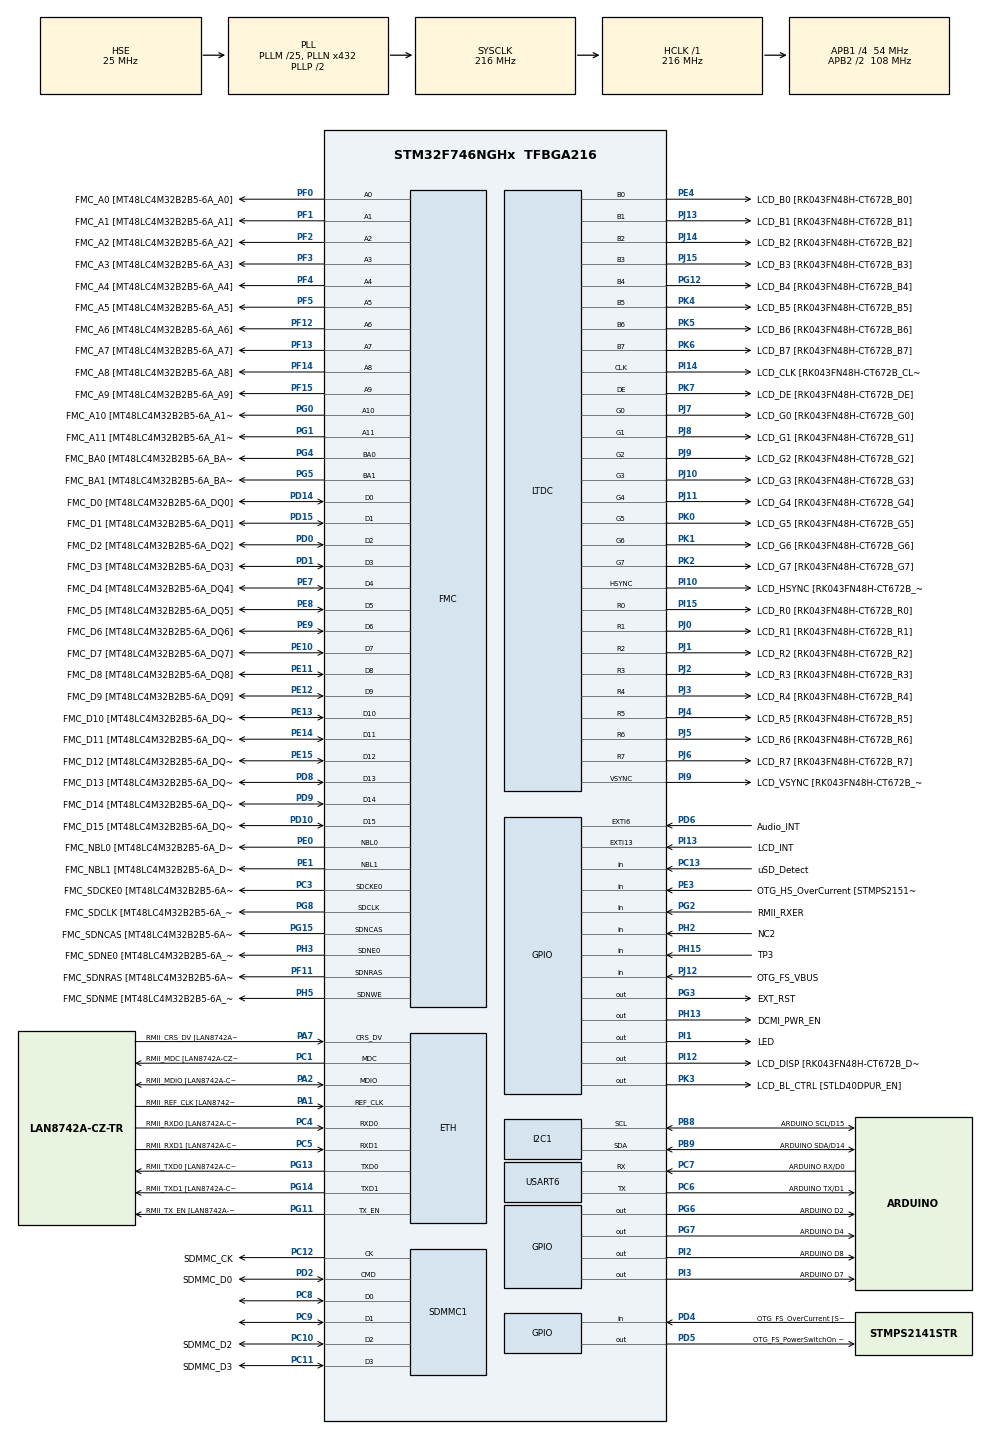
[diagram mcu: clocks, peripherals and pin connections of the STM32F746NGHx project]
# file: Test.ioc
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ETH.MediaInterface=HAL_ETH_RMII_MODE
FATFS.BSP.number=1
FATFS._USE_LFN=1
FATFS0.BSP.STBoard=false
FATFS0.BSP.api=Unknown
FATFS0.BSP.instance=PC13
FATFS0.BSP.ip=GPIO
FATFS0.BSP.mode=Input
FATFS0.BSP.name=Detect_SDIO
FATFS0.BSP.solution=PC13
FMC.CASLatency1=FMC_SDRAM_CAS_LATENCY_3
FMC.ExitSelfRefreshDelay1=7
FMC.LoadToActiveDelay1=2
FMC.RCDDelay1=2
FMC.RPDelay1=2
FMC.RPDelay2=2
FMC.RowCycleDelay1=7
FMC.RowCycleDelay2=7
FMC.SDClockPeriod1=FMC_SDRAM_CLOCK_PERIOD_2
FMC.SDClockPeriod2=FMC_SDRAM_CLOCK_PERIOD_2
FMC.SelfRefreshTime1=4
FMC.WriteRecoveryTime1=3
I2C1.Timing=0x20404768
LTDC.ActiveH=272
LTDC.ActiveW=480
LTDC.Alpha_L0=255
LTDC.BlendingFactor1_L0=LTDC_BLENDING_FACTOR1_PAxCA
LTDC.BlendingFactor2_L0=LTDC_BLENDING_FACTOR2_PAxCA
LTDC.FBStartAdress_L0=0xC0000000
LTDC.HBP=13
LTDC.HFP=32
LTDC.HSync=41
LTDC.ImageHeight_L0=272
LTDC.ImageWidth_L0=480
LTDC.Layers=0
LTDC.PixelFormat_L0=LTDC_PIXEL_FORMAT_RGB565
LTDC.VSync=10
LTDC.WindowX1_L0=480
LTDC.WindowY1_L0=272
LWIP.BSP.number=1
LWIP.LWIP_DNS=1
LWIP.MEM_SIZE=10240
LWIP.Version=v2.1.2_Cube
LWIP0.BSP.STBoard=false
LWIP0.BSP.api=BSP_COMPONENT_DRIVER
LWIP0.BSP.component=LAN8742
LWIP0.BSP.instance=LAN8742
LWIP0.BSP.name=Driver_PHY
LWIP0.BSP.semaphore=S_LAN8742
LWIP0.BSP.solution=LAN8742
Mcu.Family=STM32F7
Mcu.Name=STM32F746NGHx
Mcu.Package=TFBGA216
NVIC.DMA2D_IRQn=true\:0\:0\:false\:false\:true\:true\:true\:true
NVIC.ETH_IRQn=true\:0\:0\:false\:false\:true\:true\:true\:true
NVIC.LTDC_IRQn=true\:0\:0\:false\:false\:true\:true\:true\:true
NVIC.PriorityGroup=NVIC_PRIORITYGROUP_4
PA0/WKUP.GPIO_Label=ARDUINO A0
PA0/WKUP.GPIO_Mode=GPIO_MODE_ANALOG
PA0/WKUP.GPIO_PuPd=GPIO_NOPULL
PA0/WKUP.Signal=ADCx_IN0
PA1.GPIO_Label=RMII_REF_CLK [LAN8742A-CZ-TR_REFCLK0]
PA1.Mode=RMII
PA1.Signal=ETH_REF_CLK
PA10.GPIO_Label=OTG_FS_ID
PA10.Signal=USB_OTG_FS_ID
PA11.GPIO_Label=OTG_FS_N
PA11.Signal=USB_OTG_FS_DM
PA12.GPIO_Label=OTG_FS_P
PA12.Signal=USB_OTG_FS_DP
PA13.GPIO_Label=SWDIO
PA13.Mode=Serial_Wire
PA13.Signal=SYS_JTMS-SWDIO
PA14.GPIO_Label=SWCLK
PA14.Mode=Serial_Wire
PA14.Signal=SYS_JTCK-SWCLK
PA15.GPIO_Label=ARDUINO PWM/D9
PA15.GPIO_ModeDefaultPP=GPIO_MODE_AF_PP
PA15.GPIO_PuPd=GPIO_NOPULL
PA15.GPIO_Speed=GPIO_SPEED_FREQ_LOW
PA15.Signal=S_TIM2_CH1_ETR
PA2.GPIO_Label=RMII_MDIO [LAN8742A-CZ-TR_MDIO]
PA2.Mode=RMII
PA2.Signal=ETH_MDIO
PA3.GPIO_Label=ULPI_D0 [USB3320C-EZK_D0]
PA3.Signal=USB_OTG_HS_ULPI_D0
PA4.GPIO_Label=DCMI_HSYNC
PA4.Signal=DCMI_HSYNC
PA5.GPIO_Label=ULPI_CLK [USB3320C-EZK_CLKOUT]
PA5.Signal=USB_OTG_HS_ULPI_CK
PA6.Signal=DCMI_PIXCLK
PA7.GPIO_Label=RMII_CRS_DV [LAN8742A-CZ-TR_CRS_DV]
PA7.Mode=RMII
PA7.Signal=ETH_CRS_DV
PA8.GPIO_Label=ARDUINO PWM/D10
PA8.GPIO_ModeDefaultPP=GPIO_MODE_AF_PP
PA8.GPIO_PuPd=GPIO_NOPULL
PA8.GPIO_Speed=GPIO_SPEED_FREQ_LOW
PA8.Signal=S_TIM1_CH1
PA9.GPIO_Label=VCP_TX [STM32F103CBT6_PA3]
PA9.GPIO_Mode=GPIO_MODE_AF_PP
PA9.GPIO_PuPd=GPIO_NOPULL
PA9.GPIO_Speed=GPIO_SPEED_FREQ_LOW
PA9.Signal=USART1_TX
PB0.GPIO_Label=ULPI_D1 [USB3320C-EZK_D1]
PB0.Signal=USB_OTG_HS_ULPI_D1
PB1.GPIO_Label=ULPI_D2 [USB3320C-EZK_D2]
PB1.Signal=USB_OTG_HS_ULPI_D2
PB10.GPIO_Label=ULPI_D3 [USB3320C-EZK_D3]
PB10.Signal=USB_OTG_HS_ULPI_D3
PB11.GPIO_Label=ULPI_D4 [USB3320C-EZK_D4]
PB11.Signal=USB_OTG_HS_ULPI_D4
PB12.GPIO_Label=ULPI_D5 [USB3320C-EZK_D5]
PB12.Signal=USB_OTG_HS_ULPI_D5
PB13.GPIO_Label=ULPI_D6 [USB3320C-EZK_D6]
PB13.Signal=USB_OTG_HS_ULPI_D6
PB14.GPIO_Label=ARDUINO MISO/D12
PB14.GPIO_Mode=GPIO_MODE_AF_PP
PB14.GPIO_PuPd=GPIO_NOPULL
PB14.GPIO_Speed=GPIO_SPEED_FREQ_LOW
PB14.Signal=SPI2_MISO
PB15.GPIO_Label=ARDUINO MOSI/PWM/D11
PB15.GPIO_Mode=GPIO_MODE_AF_PP
PB15.GPIO_PuPd=GPIO_NOPULL
PB15.GPIO_Speed=GPIO_SPEED_FREQ_LOW
PB15.Signal=SPI2_MOSI
PB2.Signal=QUADSPI_CLK
PB3.GPIO_Label=SWO
PB3.Signal=SYS_JTDO-SWO
PB4.GPIO_Label=ARDUINO PWM/D3
PB4.GPIO_ModeDefaultPP=GPIO_MODE_AF_PP
PB4.GPIO_PuPd=GPIO_NOPULL
PB4.GPIO_Speed=GPIO_SPEED_FREQ_LOW
PB4.Signal=S_TIM3_CH1
PB5.GPIO_Label=ULPI_D7 [USB3320C-EZK_D7]
PB5.Signal=USB_OTG_HS_ULPI_D7
PB6.GPIO_Label=QSPI_NCS [N25Q128A13EF840E_S]
PB6.Signal=QUADSPI_BK1_NCS
PB7.GPIO_Label=VCP_RX [STM32F103CBT6_PA2]
PB7.GPIO_Mode=GPIO_MODE_AF_PP
PB7.GPIO_PuPd=GPIO_NOPULL
PB7.GPIO_Speed=GPIO_SPEED_FREQ_LOW
PB7.Signal=USART1_RX
PB8.GPIO_Label=ARDUINO SCL/D15
PB8.GPIO_Mode=GPIO_MODE_AF_OD
PB8.GPIO_PuPd=GPIO_NOPULL
PB8.GPIO_Speed=GPIO_SPEED_FREQ_LOW
PB8.Mode=I2C
PB8.Signal=I2C1_SCL
PB9.GPIO_Label=ARDUINO SDA/D14
PB9.GPIO_Mode=GPIO_MODE_AF_OD
PB9.GPIO_PuPd=GPIO_NOPULL
PB9.GPIO_Speed=GPIO_SPEED_FREQ_LOW
PB9.Mode=I2C
PB9.Signal=I2C1_SDA
PC0.GPIO_Label=ULPI_STP [USB3320C-EZK_STP]
PC0.Signal=USB_OTG_HS_ULPI_STP
PC1.GPIO_Label=RMII_MDC [LAN8742A-CZ-TR_MDC]
PC1.Mode=RMII
PC1.Signal=ETH_MDC
PC10.GPIO_Label=SDMMC_D2
PC10.Mode=SD_4_bits_Wide_bus
PC10.Signal=SDMMC1_D2
PC11.GPIO_Label=SDMMC_D3
PC11.Mode=SD_4_bits_Wide_bus
PC11.Signal=SDMMC1_D3
PC12.GPIO_Label=SDMMC_CK
PC12.Mode=SD_4_bits_Wide_bus
PC12.Signal=SDMMC1_CK
PC13.GPIO_Label=uSD_Detect
PC13.Signal=GPIO_Input
PC14/OSC32_IN.GPIO_Label=RCC_OSC32_IN
PC14/OSC32_IN.Signal=RCC_OSC32_IN
PC15/OSC32_OUT.GPIO_Label=RCC_OSC32_OUT
PC15/OSC32_OUT.Signal=RCC_OSC32_OUT
PC2.GPIO_Label=ULPI_DIR [USB3320C-EZK_DIR]
PC2.Signal=USB_OTG_HS_ULPI_DIR
PC3.GPIO_Label=FMC_SDCKE0 [MT48LC4M32B2B5-6A_CKE]
PC3.Mode=SdramChipSelect1_1
PC3.Signal=FMC_SDCKE0
PC4.GPIO_Label=RMII_RXD0 [LAN8742A-CZ-TR_RXD0]
PC4.Mode=RMII
PC4.Signal=ETH_RXD0
PC5.GPIO_Label=RMII_RXD1 [LAN8742A-CZ-TR_RXD1]
PC5.Mode=RMII
PC5.Signal=ETH_RXD1
PC6.GPIO_Label=ARDUINO TX/D1
PC6.Mode=Asynchronous
PC6.Signal=USART6_TX
PC7.GPIO_Label=ARDUINO RX/D0
PC7.Mode=Asynchronous
PC7.Signal=USART6_RX
PC8.Mode=SD_4_bits_Wide_bus
PC8.Signal=SDMMC1_D0
PC9.Mode=SD_4_bits_Wide_bus
PC9.Signal=SDMMC1_D1
PD0.GPIO_Label=FMC_D2 [MT48LC4M32B2B5-6A_DQ2]
PD0.Signal=FMC_D2_DA2
PD1.GPIO_Label=FMC_D3 [MT48LC4M32B2B5-6A_DQ3]
PD1.Signal=FMC_D3_DA3
PD10.GPIO_Label=FMC_D15 [MT48LC4M32B2B5-6A_DQ15]
PD10.Signal=FMC_D15_DA15
PD11.GPIO_Label=QSPI_D0 [N25Q128A13EF840E_DQ0]
PD11.Signal=QUADSPI_BK1_IO0
PD12.GPIO_Label=QSPI_D1 [N25Q128A13EF840E_DQ1]
PD12.Signal=QUADSPI_BK1_IO1
PD13.GPIO_Label=QSPI_D3 [N25Q128A13EF840E_DQ3]
PD13.Signal=QUADSPI_BK1_IO3
PD14.GPIO_Label=FMC_D0 [MT48LC4M32B2B5-6A_DQ0]
PD14.Signal=FMC_D0_DA0
PD15.GPIO_Label=FMC_D1 [MT48LC4M32B2B5-6A_DQ1]
PD15.Signal=FMC_D1_DA1
PD2.GPIO_Label=SDMMC_D0
PD2.Mode=SD_4_bits_Wide_bus
PD2.Signal=SDMMC1_CMD
PD3.GPIO_Label=DCMI_D5
PD3.Signal=DCMI_D5
PD4.GPIO_Label=OTG_FS_OverCurrent [STMPS2141STR_Fault]
PD4.Signal=GPIO_Input
PD5.GPIO_Label=OTG_FS_PowerSwitchOn [STMPS2141STR_EN]
PD5.PinState=GPIO_PIN_SET
PD5.Signal=GPIO_Output
PD6.GPIO_Label=Audio_INT
PD6.GPIO_ModeDefaultEXTI=GPIO_MODE_EVT_RISING
PD6.Signal=GPXTI6
PD7.GPIO_Label=SPDIF_RX0 [74LVC1G04SE_4]
PD7.Signal=SPDIFRX_IN0
PD8.GPIO_Label=FMC_D13 [MT48LC4M32B2B5-6A_DQ13]
PD8.Signal=FMC_D13_DA13
PD9.GPIO_Label=FMC_D14 [MT48LC4M32B2B5-6A_DQ14]
PD9.Signal=FMC_D14_DA14
PE0.GPIO_Label=FMC_NBL0 [MT48LC4M32B2B5-6A_DQM0]
PE0.Signal=FMC_NBL0
PE1.GPIO_Label=FMC_NBL1 [MT48LC4M32B2B5-6A_DQM1]
PE1.Signal=FMC_NBL1
PE10.GPIO_Label=FMC_D7 [MT48LC4M32B2B5-6A_DQ7]
PE10.Signal=FMC_D7_DA7
PE11.GPIO_Label=FMC_D8 [MT48LC4M32B2B5-6A_DQ8]
PE11.Signal=FMC_D8_DA8
PE12.GPIO_Label=FMC_D9 [MT48LC4M32B2B5-6A_DQ9]
PE12.Signal=FMC_D9_DA9
PE13.GPIO_Label=FMC_D10 [MT48LC4M32B2B5-6A_DQ10]
PE13.Signal=FMC_D10_DA10
PE14.GPIO_Label=FMC_D11 [MT48LC4M32B2B5-6A_DQ11]
PE14.Signal=FMC_D11_DA11
PE15.GPIO_Label=FMC_D12 [MT48LC4M32B2B5-6A_DQ12]
PE15.Signal=FMC_D12_DA12
PE2.GPIO_Label=QSPI_D2 [N25Q128A13EF840E_DQ2]
PE2.Signal=QUADSPI_BK1_IO2
PE3.GPIO_Label=OTG_HS_OverCurrent [STMPS2151STR_FAULT]
PE3.Signal=GPIO_Input
PE4.GPIO_Label=LCD_B0 [RK043FN48H-CT672B_B0]
PE4.Mode=RGB888
PE4.Signal=LTDC_B0
PE5.GPIO_Label=DCMI_D6
PE5.Signal=DCMI_D6
PE6.GPIO_Label=DCMI_D7
PE6.Signal=DCMI_D7
PE7.GPIO_Label=FMC_D4 [MT48LC4M32B2B5-6A_DQ4]
PE7.Signal=FMC_D4_DA4
PE8.GPIO_Label=FMC_D5 [MT48LC4M32B2B5-6A_DQ5]
PE8.Signal=FMC_D5_DA5
PE9.GPIO_Label=FMC_D6 [MT48LC4M32B2B5-6A_DQ6]
PE9.Signal=FMC_D6_DA6
PF0.GPIO_Label=FMC_A0 [MT48LC4M32B2B5-6A_A0]
PF0.Signal=FMC_A0
PF1.GPIO_Label=FMC_A1 [MT48LC4M32B2B5-6A_A1]
PF1.Signal=FMC_A1
PF10.GPIO_Label=ARDUINO A1
PF10.GPIO_Mode=GPIO_MODE_ANALOG
PF10.GPIO_PuPd=GPIO_NOPULL
PF10.Signal=ADC3_IN8
PF11.GPIO_Label=FMC_SDNRAS [MT48LC4M32B2B5-6A_RAS]
PF11.Signal=FMC_SDNRAS
PF12.GPIO_Label=FMC_A6 [MT48LC4M32B2B5-6A_A6]
PF12.Signal=FMC_A6
PF13.GPIO_Label=FMC_A7 [MT48LC4M32B2B5-6A_A7]
PF13.Signal=FMC_A7
PF14.GPIO_Label=FMC_A8 [MT48LC4M32B2B5-6A_A8]
PF14.Signal=FMC_A8
PF15.GPIO_Label=FMC_A9 [MT48LC4M32B2B5-6A_A9]
PF15.Signal=FMC_A9
PF2.GPIO_Label=FMC_A2 [MT48LC4M32B2B5-6A_A2]
PF2.Signal=FMC_A2
PF3.GPIO_Label=FMC_A3 [MT48LC4M32B2B5-6A_A3]
PF3.Signal=FMC_A3
PF4.GPIO_Label=FMC_A4 [MT48LC4M32B2B5-6A_A4]
PF4.Signal=FMC_A4
PF5.GPIO_Label=FMC_A5 [MT48LC4M32B2B5-6A_A5]
PF5.Signal=FMC_A5
PF6.GPIO_Label=ARDUINO A5
PF6.GPIO_Mode=GPIO_MODE_ANALOG
PF6.GPIO_PuPd=GPIO_NOPULL
PF6.Signal=ADC3_IN4
PF7.GPIO_Label=ARDUINO A4
PF7.GPIO_Mode=GPIO_MODE_ANALOG
PF7.GPIO_PuPd=GPIO_NOPULL
PF7.Signal=ADC3_IN5
PF8.GPIO_Label=ARDUINO A3
PF8.GPIO_Mode=GPIO_MODE_ANALOG
PF8.GPIO_PuPd=GPIO_NOPULL
PF8.Signal=ADC3_IN6
PF9.GPIO_Label=ARDUINO A2
PF9.GPIO_Mode=GPIO_MODE_ANALOG
PF9.GPIO_PuPd=GPIO_NOPULL
PF9.Signal=ADC3_IN7
PG0.GPIO_Label=FMC_A10 [MT48LC4M32B2B5-6A_A10]
PG0.Signal=FMC_A10
PG1.GPIO_Label=FMC_A11 [MT48LC4M32B2B5-6A_A11]
PG1.Signal=FMC_A11
PG10.GPIO_Label=SAI2_SDB [WM8994ECS/R_ADCDAT1]
PG10.Signal=SAI2_SD_B
PG11.GPIO_Label=RMII_TX_EN [LAN8742A-CZ-TR_TXEN]
PG11.Mode=RMII
PG11.Signal=ETH_TX_EN
PG12.GPIO_Label=LCD_B4 [RK043FN48H-CT672B_B4]
PG12.Mode=RGB888
PG12.Signal=LTDC_B4
PG13.GPIO_Label=RMII_TXD0 [LAN8742A-CZ-TR_TXD0]
PG13.Mode=RMII
PG13.Signal=ETH_TXD0
PG14.GPIO_Label=RMII_TXD1 [LAN8742A-CZ-TR_TXD1]
PG14.Mode=RMII
PG14.Signal=ETH_TXD1
PG15.GPIO_Label=FMC_SDNCAS [MT48LC4M32B2B5-6A_CAS]
PG15.Signal=FMC_SDNCAS
PG2.GPIO_Label=RMII_RXER
PG2.Signal=GPIO_Input
PG3.GPIO_Label=EXT_RST
PG3.Signal=GPIO_Output
PG4.GPIO_Label=FMC_BA0 [MT48LC4M32B2B5-6A_BA0]
PG4.Signal=FMC_A14_BA0
PG5.GPIO_Label=FMC_BA1 [MT48LC4M32B2B5-6A_BA1]
PG5.Signal=FMC_A15_BA1
PG6.GPIO_Label=ARDUINO D2
PG6.Signal=GPIO_Output
PG7.GPIO_Label=ARDUINO D4
PG7.Signal=GPIO_Output
PG8.GPIO_Label=FMC_SDCLK [MT48LC4M32B2B5-6A_CLK]
PG8.Signal=FMC_SDCLK
PG9.GPIO_Label=DCMI_VSYNC
PG9.Signal=DCMI_VSYNC
PH0/OSC_IN.GPIO_Label=OSC_25M [NZ2520SB-25.00M_OUT]
PH0/OSC_IN.Mode=HSE-External-Oscillator
PH0/OSC_IN.Signal=RCC_OSC_IN
PH1/OSC_OUT.Mode=HSE-External-Oscillator
PH1/OSC_OUT.Signal=RCC_OSC_OUT
PH10.GPIO_Label=DCMI_D1
PH10.Signal=DCMI_D1
PH11.GPIO_Label=DCMI_D2
PH11.Signal=DCMI_D2
PH12.GPIO_Label=DCMI_D3
PH12.Signal=DCMI_D3
PH13.GPIO_Label=DCMI_PWR_EN
PH13.Signal=GPIO_Output
PH14.GPIO_Label=DCMI_D4
PH14.Signal=DCMI_D4
PH15.GPIO_Label=TP3
PH15.Signal=GPIO_Input
PH2.GPIO_Label=NC2
PH2.Signal=GPIO_Input
PH3.GPIO_Label=FMC_SDNE0 [MT48LC4M32B2B5-6A_CS]
PH3.Mode=SdramChipSelect1_1
PH3.Signal=FMC_SDNE0
PH4.GPIO_Label=ULPI_NXT [USB3320C-EZK_NXT]
PH4.Signal=USB_OTG_HS_ULPI_NXT
PH5.GPIO_Label=FMC_SDNME [MT48LC4M32B2B5-6A_WE]
PH5.Signal=FMC_SDNWE
PH6.GPIO_Label=ARDUINO PWM/D6
PH6.Signal=S_TIM12_CH1
PH7.GPIO_Label=LCD_SCL [RK043FN48H-CT672B_SCL]
PH7.Signal=I2C3_SCL
PH8.GPIO_Label=LCD_SDA [RK043FN48H-CT672B_SDA]
PH8.Signal=I2C3_SDA
PH9.GPIO_Label=DCMI_D0
PH9.Signal=DCMI_D0
PI0.GPIO_Label=ARDUINO PWM/CS/D5
PI0.GPIO_ModeDefaultPP=GPIO_MODE_AF_PP
PI0.GPIO_PuPd=GPIO_NOPULL
PI0.GPIO_Speed=GPIO_SPEED_FREQ_LOW
PI0.Signal=S_TIM5_CH4
PI1.GPIO_Label=LED
PI1.Signal=GPIO_Output
PI10.GPIO_Label=LCD_HSYNC [RK043FN48H-CT672B_HSYNC]
PI10.Mode=RGB888
PI10.Signal=LTDC_HSYNC
PI12.GPIO_Label=LCD_DISP [RK043FN48H-CT672B_DISP] 
PI12.Signal=GPIO_Output
PI13.GPIO_Label=LCD_INT
PI13.GPIO_ModeDefaultEXTI=GPIO_MODE_EVT_RISING
PI13.Signal=GPXTI13
PI14.GPIO_Label=LCD_CLK [RK043FN48H-CT672B_CLK]
PI14.Mode=RGB888
PI14.Signal=LTDC_CLK
PI15.GPIO_Label=LCD_R0 [RK043FN48H-CT672B_R0]
PI15.Mode=RGB888
PI15.Signal=LTDC_R0
PI2.GPIO_Label=ARDUINO D8
PI2.Signal=GPIO_Output
PI3.GPIO_Label=ARDUINO D7
PI3.Signal=GPIO_Output
PI4.GPIO_Label=SAI2_MCLKA [WM8994ECS/R_MCLK1]
PI4.Signal=SAI2_MCLK_A
PI5.GPIO_Label=SAI2_SCKA [WM8994ECS/R_BCLK1]
PI5.Signal=SAI2_SCK_A
PI6.GPIO_Label=SAI2_SDA [WM8994ECS/R_DACDAT1]
PI6.Signal=SAI2_SD_A
PI7.GPIO_Label=SAI2_FSA [WM8994ECS/R_LRCLK1]
PI7.Signal=SAI2_FS_A
PI8.GPIO_Label=NC1 [TP2]
PI8.Signal=RTC_TS
PI9.GPIO_Label=LCD_VSYNC [RK043FN48H-CT672B_VSYNC]
PI9.Mode=RGB888
PI9.Signal=LTDC_VSYNC
PJ0.GPIO_Label=LCD_R1 [RK043FN48H-CT672B_R1]
PJ0.Mode=RGB888
PJ0.Signal=LTDC_R1
PJ1.GPIO_Label=LCD_R2 [RK043FN48H-CT672B_R2]
PJ1.Mode=RGB888
PJ1.Signal=LTDC_R2
PJ10.GPIO_Label=LCD_G3 [RK043FN48H-CT672B_G3]
PJ10.Mode=RGB888
PJ10.Signal=LTDC_G3
PJ11.GPIO_Label=LCD_G4 [RK043FN48H-CT672B_G4]
PJ11.Mode=RGB888
PJ11.Signal=LTDC_G4
PJ12.GPIO_Label=OTG_FS_VBUS
PJ12.Signal=GPIO_Input
PJ13.GPIO_Label=LCD_B1 [RK043FN48H-CT672B_B1]
PJ13.Mode=RGB888
PJ13.Signal=LTDC_B1
PJ14.GPIO_Label=LCD_B2 [RK043FN48H-CT672B_B2]
PJ14.Mode=RGB888
PJ14.Signal=LTDC_B2
PJ15.GPIO_Label=LCD_B3 [RK043FN48H-CT672B_B3]
PJ15.Mode=RGB888
PJ15.Signal=LTDC_B3
PJ2.GPIO_Label=LCD_R3 [RK043FN48H-CT672B_R3]
PJ2.Mode=RGB888
PJ2.Signal=LTDC_R3
PJ3.GPIO_Label=LCD_R4 [RK043FN48H-CT672B_R4]
PJ3.Mode=RGB888
PJ3.Signal=LTDC_R4
PJ4.GPIO_Label=LCD_R5 [RK043FN48H-CT672B_R5]
PJ4.Mode=RGB888
PJ4.Signal=LTDC_R5
PJ5.GPIO_Label=LCD_R6 [RK043FN48H-CT672B_R6]
PJ5.Mode=RGB888
PJ5.Signal=LTDC_R6
PJ6.GPIO_Label=LCD_R7 [RK043FN48H-CT672B_R7]
PJ6.Mode=RGB888
PJ6.Signal=LTDC_R7
PJ7.GPIO_Label=LCD_G0 [RK043FN48H-CT672B_G0]
PJ7.Mode=RGB888
PJ7.Signal=LTDC_G0
PJ8.GPIO_Label=LCD_G1 [RK043FN48H-CT672B_G1]
PJ8.Mode=RGB888
PJ8.Signal=LTDC_G1
PJ9.GPIO_Label=LCD_G2 [RK043FN48H-CT672B_G2]
PJ9.Mode=RGB888
PJ9.Signal=LTDC_G2
PK0.GPIO_Label=LCD_G5 [RK043FN48H-CT672B_G5]
PK0.Mode=RGB888
PK0.Signal=LTDC_G5
PK1.GPIO_Label=LCD_G6 [RK043FN48H-CT672B_G6]
PK1.Mode=RGB888
PK1.Signal=LTDC_G6
PK2.GPIO_Label=LCD_G7 [RK043FN48H-CT672B_G7]
PK2.Mode=RGB888
PK2.Signal=LTDC_G7
PK3.GPIO_Label=LCD_BL_CTRL [STLD40DPUR_EN]
PK3.Signal=GPIO_Output
PK4.GPIO_Label=LCD_B5 [RK043FN48H-CT672B_B5]
PK4.Mode=RGB888
PK4.Signal=LTDC_B5
PK5.GPIO_Label=LCD_B6 [RK043FN48H-CT672B_B6]
PK5.Mode=RGB888
PK5.Signal=LTDC_B6
PK6.GPIO_Label=LCD_B7 [RK043FN48H-CT672B_B7]
PK6.Mode=RGB888
PK6.Signal=LTDC_B7
PK7.GPIO_Label=LCD_DE [RK043FN48H-CT672B_DE]
PK7.Mode=RGB888
PK7.Signal=LTDC_DE
ProjectManager.HeapSize=0x200
ProjectManager.StackSize=0x1000
ProjectManager.TargetToolchain=MDK-ARM V5.32
RCC.AHBFreq_Value=216000000
RCC.APB1CLKDivider=RCC_HCLK_DIV4
RCC.APB1Freq_Value=54000000
RCC.APB1TimFreq_Value=108000000
RCC.APB2CLKDivider=RCC_HCLK_DIV2
RCC.APB2Freq_Value=108000000
RCC.APB2TimFreq_Value=216000000
RCC.CortexFreq_Value=216000000
RCC.HCLKFreq_Value=216000000
RCC.HSE_VALUE=25000000
RCC.HSI_VALUE=16000000
RCC.LSE_VALUE=32768
RCC.PLLM=25
RCC.PLLN=432
RCC.PLLQ=9
RCC.PLLSAIN=384
RCC.PLLSAIR=5
RCC.PLLSAIRDiv=RCC_PLLSAIDIVR_8
RCC.PLLSourceVirtual=RCC_PLLSOURCE_HSE
RCC.SDMMCClockSelection=RCC_SDMMC1CLKSOURCE_CLK48
RCC.SYSCLKFreq_VALUE=216000000
RCC.SYSCLKSource=RCC_SYSCLKSOURCE_PLLCLK
RCC.USBFreq_Value=48000000
RCC.VCOOutputFreq_Value=432000000
SH.ADCx_IN0.0=ADC3_IN0
SH.FMC_A0.0=FMC_A0,12b-sda1
SH.FMC_A1.0=FMC_A1,12b-sda1
SH.FMC_A10.0=FMC_A10,12b-sda1
SH.FMC_A11.0=FMC_A11,12b-sda1
SH.FMC_A14_BA0.0=FMC_BA0,FourSdramBanks1
SH.FMC_A15_BA1.0=FMC_BA1,FourSdramBanks1
SH.FMC_A2.0=FMC_A2,12b-sda1
SH.FMC_A3.0=FMC_A3,12b-sda1
SH.FMC_A4.0=FMC_A4,12b-sda1
SH.FMC_A5.0=FMC_A5,12b-sda1
SH.FMC_A6.0=FMC_A6,12b-sda1
SH.FMC_A7.0=FMC_A7,12b-sda1
SH.FMC_A8.0=FMC_A8,12b-sda1
SH.FMC_A9.0=FMC_A9,12b-sda1
SH.FMC_D0_DA0.0=FMC_D0,sd-16b-d1
SH.FMC_D10_DA10.0=FMC_D10,sd-16b-d1
SH.FMC_D11_DA11.0=FMC_D11,sd-16b-d1
SH.FMC_D12_DA12.0=FMC_D12,sd-16b-d1
SH.FMC_D13_DA13.0=FMC_D13,sd-16b-d1
SH.FMC_D14_DA14.0=FMC_D14,sd-16b-d1
SH.FMC_D15_DA15.0=FMC_D15,sd-16b-d1
SH.FMC_D1_DA1.0=FMC_D1,sd-16b-d1
SH.FMC_D2_DA2.0=FMC_D2,sd-16b-d1
SH.FMC_D3_DA3.0=FMC_D3,sd-16b-d1
SH.FMC_D4_DA4.0=FMC_D4,sd-16b-d1
SH.FMC_D5_DA5.0=FMC_D5,sd-16b-d1
SH.FMC_D6_DA6.0=FMC_D6,sd-16b-d1
SH.FMC_D7_DA7.0=FMC_D7,sd-16b-d1
SH.FMC_D8_DA8.0=FMC_D8,sd-16b-d1
SH.FMC_D9_DA9.0=FMC_D9,sd-16b-d1
SH.FMC_NBL0.0=FMC_NBL0,Sd2ByteEnable1
SH.FMC_NBL1.0=FMC_NBL1,Sd2ByteEnable1
SH.FMC_SDCLK.0=FMC_SDCLK,12b-sda1
SH.FMC_SDNCAS.0=FMC_SDNCAS,12b-sda1
SH.FMC_SDNRAS.0=FMC_SDNRAS,12b-sda1
SH.FMC_SDNWE.0=FMC_SDNWE,12b-sda1
SH.S_TIM12_CH1.0=TIM12_CH1
SH.S_TIM1_CH1.0=TIM1_CH1
SH.S_TIM2_CH1_ETR.0=TIM2_CH1
SH.S_TIM3_CH1.0=TIM3_CH1
SH.S_TIM5_CH4.0=TIM5_CH4
USART6.VirtualMode-Asynchronous=VM_ASYNC
VP_DMA2D_VS_DMA2D.Mode=DMA2D_Activate
VP_FATFS_VS_SDIO.Mode=SDIO
VP_LWIP_VS_Enabled.Mode=Enabled
board=STM32F746G-DISCO

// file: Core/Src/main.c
/* USER CODE BEGIN Header */
/**
  ******************************************************************************
  * @file           : main.c
  * @brief          : Main program body
  ******************************************************************************
  * @attention
  *
  * Copyright (c) 2026 STMicroelectronics.
  * All rights reserved.
  *
  * This software is licensed under terms that can be found in the LICENSE file
  * in the root directory of this software component.
  * If no LICENSE file comes with this software, it is provided AS-IS.
  *
  ******************************************************************************
  */
/* USER CODE END Header */
#include "main.h"
#include "fatfs.h"
#include "lwip.h"

/* USER CODE BEGIN Includes */
#include "stm32746g_discovery_lcd.h"
#include "stm32746g_discovery_sdram.h"
#include "stm32746g_discovery.h"
#include "ds3231.h"
#include "dht22.h"
#include "ds18b20.h"
#include "peltier.h"
#include "ui.h"
#include "screen.h"
#include "logctrl.h"
#include "sdlog.h"
#include "exp.h"
#include "lwip/sio.h"
#include "net.h"
#include "aio.h"
#include "fatfs_platform.h"
#include <string.h>
#include <stdio.h>
#include <stdarg.h>
/* USER CODE END Includes */

/* USER CODE BEGIN PD */
/* ---------------- Sensor haberlesme pinleri ----------------
 *  Arduino   MCU    Sensor     Konum
 *  D2        PG6    DS18B20    dis ortam
 *  D3        PB4    DS18B20    ic sogutucu tabani (Peltier tarafi)
 *  D4        PG7    DS18B20    karsi duvar yuzeyi
 *  D5        PI0    DHT22      kabin ortasi: hava sicakligi + nem (kontrol edilen)
 *  Her DS18B20 hattina 3.3V'a pull-up (4.7k ideal, kisa kabloda 10k).
 */

#define DS18B20_AMBIENT_GPIO_Port  GPIOG
#define DS18B20_AMBIENT_Pin        GPIO_PIN_6     /* D2 */

#define DS18B20_HEATSINK_GPIO_Port GPIOB
#define DS18B20_HEATSINK_Pin       GPIO_PIN_4     /* D3 */

#define DS18B20_WALL_GPIO_Port     GPIOG
#define DS18B20_WALL_Pin           GPIO_PIN_7     /* D4 */

#define DHT22_AIR_GPIO_Port        GPIOI
#define DHT22_AIR_Pin              GPIO_PIN_0     /* D5 */

#define SAMPLE_PERIOD_MS           1000U          /* ornekleme/log periyodu: 1 Hz */
/* USER CODE END PD */

DMA2D_HandleTypeDef hdma2d;

I2C_HandleTypeDef hi2c1;

LTDC_HandleTypeDef hltdc;

SD_HandleTypeDef hsd1;

UART_HandleTypeDef huart6;

SDRAM_HandleTypeDef hsdram1;

void SystemClock_Config(void);
static void MX_GPIO_Init(void);
static void MX_DMA2D_Init(void);
static void MX_FMC_Init(void);
static void MX_LTDC_Init(void);
static void MX_I2C1_Init(void);
static void MX_SDMMC1_SD_Init(void);
static void MX_USART6_UART_Init(void);
/* USER CODE BEGIN PFP */
static uint8_t Button_IsPressed(void);
static void Draw_StartupScreen(void);
static void UI_UpdateSensors(void);
static void UI_UpdatePeltier(uint8_t force);
static void UI_UpdateSd(void);
static void UI_UpdateExp(uint8_t force);
static void UI_UpdateNet(uint8_t force);
static void Aio_Fill(Aio_Data *a);
static void Fmt_Fixed(char *buf, size_t n, int32_t v, int32_t scale);
/* USER CODE END PFP */

/* USER CODE BEGIN 0 */
/* ---------------- Kapak anahtari (D7 = PI3) ----------------
 * Anahtar kapak kapaliyken pini GND'ye ceker: D7 = 0 kapali, D7 = 1 acik.
 * Ic pull-up acik; anahtar takili degilse kapak "acik" gorunur.
 * CubeMX D7'yi cikis olarak tanimliyor; MX_GPIO_Init'ten sonra burada
 * girise cevrilir (CubeMX'te de PI3 = GPIO_Input, Pull-up yapilabilir). */
#define DOOR_GPIO_Port      GPIOI
#define DOOR_Pin            GPIO_PIN_3
#define DOOR_DEBOUNCE_MS    50U

static uint8_t  door_open;          /* kararli durum: 1 = acik */
static uint8_t  door_raw;
static uint32_t door_t;

static void Door_Init(void)
{
  GPIO_InitTypeDef g = {0};
  g.Pin   = DOOR_Pin;
  g.Mode  = GPIO_MODE_INPUT;
  g.Pull  = GPIO_PULLUP;
  g.Speed = GPIO_SPEED_FREQ_LOW;
  HAL_GPIO_Init(DOOR_GPIO_Port, &g);
  HAL_Delay(2);                     /* pull-up otursun */
  door_raw  = (HAL_GPIO_ReadPin(DOOR_GPIO_Port, DOOR_Pin) == GPIO_PIN_SET) ? 1U : 0U;
  door_open = door_raw;
  door_t    = HAL_GetTick();
}

/* Her dongude cagrilir; kararli durum degisince 1 doner (50 ms sabit kalmali). */
static uint8_t Door_Task(void)
{
  uint8_t  raw = (HAL_GPIO_ReadPin(DOOR_GPIO_Port, DOOR_Pin) == GPIO_PIN_SET) ? 1U : 0U;
  uint32_t now = HAL_GetTick();
  if (raw != door_raw) { door_raw = raw; door_t = now; return 0U; }
  if (raw != door_open && (now - door_t) >= DOOR_DEBOUNCE_MS)
  {
    door_open = raw;
    return 1U;
  }
  return 0U;
}

/* Sensor nesneleri (pinler: USER CODE PD bolumu) */
static DHT22_HandleTypeDef   hdht22;
static DS18B20_HandleTypeDef hds_heatsink;
static DS18B20_HandleTypeDef hds_wall;
static DS18B20_HandleTypeDef hds_ambient;
static DS18B20_HandleTypeDef *const ds_list[3] = { &hds_heatsink, &hds_wall, &hds_ambient };

static uint32_t sample_count = 0;
static uint8_t  rtc_last_sec = 0xFF;   /* 0xFF: saat bir sonraki dongude yeniden cizilsin */

/* USER CODE END 0 */

int main(void)
{

  /* MCU Configuration--------------------------------------------------------*/

  /* Reset of all peripherals, Initializes the Flash interface and the Systick. */
  HAL_Init();

  /* Configure the system clock */
  SystemClock_Config();

  /* Initialize all configured peripherals */
  MX_GPIO_Init();
  MX_DMA2D_Init();
  MX_FMC_Init();
  MX_LTDC_Init();
  MX_I2C1_Init();
  MX_SDMMC1_SD_Init();
  MX_FATFS_Init();
  MX_USART6_UART_Init();
  MX_LWIP_Init();
  /* USER CODE BEGIN 2 */
  /* SDMMC saati: 48 MHz / (ClockDiv + 2). CubeMX'teki 0 (24 MHz) polling modunda
   * FIFO tasmasina/eksik veriye yol acabiliyor; 1 Hz kayit icin 12 MHz fazlasiyla
   * yeterli. HAL_SD_Init f_mount sirasinda cagrildigi icin burada ayarlamak yeterli. */
  hsd1.Init.ClockDiv = 2U;
  Debug_UART_Init();          /* printf -> USART1 (ST-LINK sanal COM) */
  Door_Init();                /* D7 kapak anahtari: giris + pull-up  */
  Peltier_Init(&huart6);      /* USART6 -> Peltier surucu karti       */

  if (BSP_LCD_Init() != LCD_OK)
  {
    Error_Handler();
  }
  BSP_LCD_LayerDefaultInit(0, LCD_FB_START_ADDRESS);
  BSP_LCD_SelectLayer(0);

  BSP_LCD_SetBackColor(LCD_COLOR_BLACK);
  BSP_LCD_SetTextColor(LCD_COLOR_WHITE);
  BSP_LCD_Clear(LCD_COLOR_BLACK);

  BSP_LCD_SetFont(&Font24);
  BSP_LCD_DisplayStringAt(0, 20, (uint8_t *)"Akilli Iklim Sistemi", CENTER_MODE);
  BSP_LCD_SetFont(&Font16);
  BSP_LCD_DrawRect(20, 60, 440, 150);
  BSP_LCD_DisplayStringAt(20, 80, (uint8_t *)"RTC DS3231", LEFT_MODE);

  DS3231_TimeDate rtc = {0};
  uint8_t rtc_ok = 0;

  if (DS3231_Init(&hi2c1))
  {
    BSP_LCD_DisplayStringAt(20, 110, (uint8_t *)"RTC Basarili", LEFT_MODE);
  }
  else
  {
    BSP_LCD_DisplayStringAt(20, 110, (uint8_t *)"RTC Bulunamadi", LEFT_MODE);
  }

  BSP_PB_Init(BUTTON_WAKEUP, BUTTON_MODE_GPIO);
  DHT22_Init(&hdht22, DHT22_AIR_GPIO_Port, DHT22_AIR_Pin);
  Ds18B20_Init(&hds_heatsink, DS18B20_HEATSINK_GPIO_Port, DS18B20_HEATSINK_Pin, "Sogutucu");
  Ds18B20_Init(&hds_wall,     DS18B20_WALL_GPIO_Port,     DS18B20_WALL_Pin,     "Duvar");
  Ds18B20_Init(&hds_ambient,  DS18B20_AMBIENT_GPIO_Port,  DS18B20_AMBIENT_Pin,  "Dis ortam");
  LogCtrl_Init(&hi2c1);       /* 24C32: kayit durumu; aciksa kayda devam   */
  SdLog_Init();               /* SD kart TXT kaydi                         */
  rtc_ok = DS3231_GetTimeDate(&hi2c1, &rtc);
  Exp_Init(&hi2c1, &rtc, rtc_ok);   /* deney: calisan test varsa kaldigi yerden */
  Aio_Init();                       /* Adafruit IO MQTT istemcisi (netcfg.h)    */
  Screen_Init(&hi2c1);        /* dokunmatik panel + ekran durum makinesi   */
  printf("\r\n%s\r\n", SDLOG_COLUMNS);
  Draw_StartupScreen();
  /* USER CODE END 2 */

  /* Infinite loop */
  /* USER CODE BEGIN WHILE */
  uint8_t button_down = 0;
  uint8_t long_press_done = 0;
  uint32_t press_started_at = 0;
  uint32_t last_print_tick = 0;
  uint32_t last_sample_tick = HAL_GetTick();
  uint8_t  sample_last_sec  = 0xFFU;      /* son orneklenen RTC saniyesi */

  while (1)
  {
    /* USER CODE END WHILE */

    /* USER CODE BEGIN 3 */
    /* ---------------- Ethernet / LwIP (bloklamaz) ----------------
     * Gelen paketleri isler, LwIP zamanlayicilarini (DHCP, ARP, TCP) calistirir,
     * 100 ms'de bir kablo durumunu kontrol eder. Her dongude cagrilmali. */
    MX_LWIP_Process();

    /* ---------------- Haberlesme gorevleri (bloklamaz) ---------------- */
    Peltier_Task();             /* komut tekrari, onay takibi            */
    Debug_Task();               /* konsol: *<deger># , *S#               */

    /* ---------------- Saat oku ---------------- */
    rtc_ok = DS3231_GetTimeDate(&hi2c1, &rtc);

    /* ---------------- Kapak anahtari: acilis/kapanis olay olarak kaydedilir ---------------- */
    if (Door_Task())
    {
      if (rtc_ok) Exp_MarkEvent(door_open ? EXP_EVT_DOOR : EXP_EVT_DOOR_CLOSE, &rtc);
      printf("KAPAK %s\r\n", door_open ? "ACILDI" : "KAPANDI");
      Screen_Wake();
      if (Screen_Current() == SCREEN_MAIN) UI_DrawDoor(door_open);
    }

    /* ---------------- Dokunmatik + ekran durum makinesi (bloklamaz) ---------------- */
    Screen_Task(&rtc, rtc_ok);

    /* ---------------- SD kart: tak/cikar, mount, dosya ac/kapat ---------------- */
    SdLog_Task(LogCtrl_IsActive(), &rtc, rtc_ok);

    /* Ana ekran parcalari yalnizca ana ekrandayken cizilir */
    if (Screen_Current() == SCREEN_MAIN)
    {
      UI_UpdatePeltier(0);      /* komut/baglanti degistiyse paneli ciz  */
      if (!rtc_ok || rtc.seconds != rtc_last_sec)
      {
        rtc_last_sec = rtc_ok ? rtc.seconds : 0xFF;
        UI_DrawClock(&rtc, rtc_ok);
      }
    }

    /* ---------------- Sensor gorevleri (bloklamaz) ----------------
     * Her cagrida yalnizca sirasi gelen kisa islem yapilir; DS18B20'nin
     * 750 ms donusum suresi ve DHT22'nin 2 s araligi beklenmez. */
    DHT22_Task(&hdht22);
    for (uint8_t k = 0; k < 3; k++)
    {
      Ds18B20_Task(ds_list[k]);
    }

    /* ---------------- 1 Hz ornekleme ----------------
     * RTC saniyesi degisince bir ornek alinir: her gercek saniyeye tam bir satir.
     * (P1 on testinde HAL_GetTick ile 1000 ms beklemek, dongu gecikmesi ve DHT22
     * okumasindaki kesme kapatma yuzunden 22 saatte 563 saniyeyi atlatti.)
     * RTC okunamazsa HAL_GetTick ile 1000 ms'ye geri donulur. */
    if (rtc_ok ? (rtc.seconds != sample_last_sec)
               : (HAL_GetTick() - last_sample_tick >= SAMPLE_PERIOD_MS))
    {
      char tAir[12], rhAir[12], tHs[12], tWall[12], tAmb[12];
      last_sample_tick = HAL_GetTick();
      sample_last_sec  = rtc_ok ? rtc.seconds : 0xFFU;

      /* Sensorlerin en son gecerli degerleri alinir (okuma Task'larda yapildi) */
      sample_count++;

      /* ---------------- Deney: komutu hesapla ve Peltier'e gonder ---------------- */
      {
        Exp_Inputs ein;
        ein.air_valid     = (hdht22.valid && hdht22.last_status == DHT22_OK) ? 1U : 0U;
        ein.air_x10       = hdht22.temperature_x10;
        ein.peltier_valid = (hds_heatsink.status == DS18B20_OK) ? 1U : 0U;   /* D3: Peltier yuzeyi */
        ein.peltier_x100  = hds_heatsink.temperature_x100;
        Exp_Task1Hz(&ein, &rtc, rtc_ok);
      }

      /* Ekran isigi kapaliysa deney durumu ya da guvenlik degisince ac */
      {
        static Exp_State  w_state  = EXP_IDLE;
        static Exp_Safety w_safety = EXP_SAFE_OK;
        const Exp_Status *es = Exp_GetStatus();
        if (es->state != w_state || es->safety != w_safety) Screen_Wake();
        w_state  = es->state;
        w_safety = es->safety;
      }

      Net_Task1Hz();            /* kablo / IP / sunucu durumu, degisince log */
      {
        Aio_Data ad;
        Aio_Fill(&ad);
        Aio_Task1Hz(&ad);       /* Adafruit IO: baglanti + 20 s'de bir gonderim */
      }

      if (Screen_Current() == SCREEN_MAIN)
      {
        UI_UpdateSensors();
        UI_UpdatePeltier(1);
        UI_UpdateSd();
        UI_UpdateExp(0);
        UI_UpdateNet(0);
      }

      /* Ornek satiri (son okuma hataliysa alan bos birakilir):
       * seri porta her zaman, SD karta kayit aciksa yazilir */
      tAir[0] = rhAir[0] = tHs[0] = tWall[0] = tAmb[0] = '\0';
      if (hdht22.valid && hdht22.last_status == DHT22_OK)
      {
        Fmt_Fixed(tAir,  sizeof(tAir),  hdht22.temperature_x10, 10);
        Fmt_Fixed(rhAir, sizeof(rhAir), (int32_t)hdht22.humidity_x10, 10);
      }
      if (hds_heatsink.status == DS18B20_OK) Fmt_Fixed(tHs,   sizeof(tHs),   hds_heatsink.temperature_x100, 100);
      if (hds_wall.status     == DS18B20_OK) Fmt_Fixed(tWall, sizeof(tWall), hds_wall.temperature_x100,     100);
      if (hds_ambient.status  == DS18B20_OK) Fmt_Fixed(tAmb,  sizeof(tAmb),  hds_ambient.temperature_x100,  100);
      {
        char line[160], sp[12], ureq[8];
        const Exp_Status *es = Exp_GetStatus();
        uint8_t exp_on = (es->state == EXP_RUNNING || es->state == EXP_PAUSED) ? 1U : 0U;
        sp[0] = '\0';
        ureq[0] = '\0';
        if (exp_on && es->closed && es->state == EXP_RUNNING) Fmt_Fixed(sp, sizeof(sp), es->sp_x10, 10);
        if (exp_on) snprintf(ureq, sizeof(ureq), "%d", (int)es->u_req);   /* deneyin istedigi komut */
        snprintf(line, sizeof(line), "%02u/%02u/20%02u,%02u:%02u:%02u,%lu,%s,%s,%s,%s,%s,%d,%u,%u,%u,%s,%u,%u,,%s,%u",
                 rtc.date, rtc.month, rtc.year, rtc.hours, rtc.minutes, rtc.seconds,
                 (unsigned long)(HAL_GetTick() / 1000U), tAir, rhAir, tHs, tWall, tAmb,
                 Peltier_GetCommand(), (unsigned)Peltier_IsLinkOk(),
                 exp_on ? (unsigned)es->proc : 0U, exp_on ? (unsigned)es->phase : 0U, sp,
                 (unsigned)Exp_TakeEvent(), exp_on ? (unsigned)es->safety : 0U, ureq, (unsigned)door_open);
        printf("%s\r\n", line);
        if (LogCtrl_IsActive())
        {
          SdLog_WriteLine(line, &rtc);
        }
      }
    }

    if (Button_IsPressed())
    {
      if (!button_down)
      {
        button_down = 1;
        press_started_at = HAL_GetTick();
        long_press_done = 0;
      }
      else if (!long_press_done && (HAL_GetTick() - press_started_at) >= 2000)
      {
        /* Yedek yol: user butonuna 2 s basinca dokunmatik saat ayar sayfasi acilir */
        Screen_Wake();
        if (Screen_Current() == SCREEN_MAIN)
        {
          Screen_OpenClockSetup(&rtc);
        }
        long_press_done = 1;
      }
    }
    else if (button_down)
    {
      button_down = 0;
      long_press_done = 0;
    }

    if (HAL_GetTick() - last_print_tick >= 1000)
    {
      last_print_tick = HAL_GetTick();
    }

    HAL_GPIO_TogglePin(LED_GPIO_Port, LED_Pin);
    HAL_Delay(20);
  }
  /* USER CODE END 3 */
}

void SystemClock_Config(void)
{
  RCC_OscInitTypeDef RCC_OscInitStruct = {0};
  RCC_ClkInitTypeDef RCC_ClkInitStruct = {0};

  /** Configure the main internal regulator output voltage
  */
  __HAL_RCC_PWR_CLK_ENABLE();
  __HAL_PWR_VOLTAGESCALING_CONFIG(PWR_REGULATOR_VOLTAGE_SCALE1);

  /** Initializes the RCC Oscillators according to the specified parameters
  * in the RCC_OscInitTypeDef structure.
  */
  RCC_OscInitStruct.OscillatorType = RCC_OSCILLATORTYPE_HSE;
  RCC_OscInitStruct.HSEState = RCC_HSE_ON;
  RCC_OscInitStruct.PLL.PLLState = RCC_PLL_ON;
  RCC_OscInitStruct.PLL.PLLSource = RCC_PLLSOURCE_HSE;
  RCC_OscInitStruct.PLL.PLLM = 25;
  RCC_OscInitStruct.PLL.PLLN = 432;
  RCC_OscInitStruct.PLL.PLLP = RCC_PLLP_DIV2;
  RCC_OscInitStruct.PLL.PLLQ = 9;
  if (HAL_RCC_OscConfig(&RCC_OscInitStruct) != HAL_OK)
  {
    Error_Handler();
  }

  /** Activate the Over-Drive mode
  */
  if (HAL_PWREx_EnableOverDrive() != HAL_OK)
  {
    Error_Handler();
  }

  /** Initializes the CPU, AHB and APB buses clocks
  */
  RCC_ClkInitStruct.ClockType = RCC_CLOCKTYPE_HCLK|RCC_CLOCKTYPE_SYSCLK
                              |RCC_CLOCKTYPE_PCLK1|RCC_CLOCKTYPE_PCLK2;
  RCC_ClkInitStruct.SYSCLKSource = RCC_SYSCLKSOURCE_PLLCLK;
  RCC_ClkInitStruct.AHBCLKDivider = RCC_SYSCLK_DIV1;
  RCC_ClkInitStruct.APB1CLKDivider = RCC_HCLK_DIV4;
  RCC_ClkInitStruct.APB2CLKDivider = RCC_HCLK_DIV2;

  if (HAL_RCC_ClockConfig(&RCC_ClkInitStruct, FLASH_LATENCY_7) != HAL_OK)
  {
    Error_Handler();
  }
}

static void MX_DMA2D_Init(void)
{

  hdma2d.Instance = DMA2D;
  hdma2d.Init.Mode = DMA2D_M2M;
  hdma2d.Init.ColorMode = DMA2D_OUTPUT_ARGB8888;
  hdma2d.Init.OutputOffset = 0;
  hdma2d.LayerCfg[1].InputOffset = 0;
  hdma2d.LayerCfg[1].InputColorMode = DMA2D_INPUT_ARGB8888;
  hdma2d.LayerCfg[1].AlphaMode = DMA2D_NO_MODIF_ALPHA;
  hdma2d.LayerCfg[1].InputAlpha = 0;
  if (HAL_DMA2D_Init(&hdma2d) != HAL_OK)
  {
    Error_Handler();
  }
  if (HAL_DMA2D_ConfigLayer(&hdma2d, 1) != HAL_OK)
  {
    Error_Handler();
  }

}

static void MX_I2C1_Init(void)
{

  hi2c1.Instance = I2C1;
  hi2c1.Init.Timing = 0x20404768;
  hi2c1.Init.OwnAddress1 = 0;
  hi2c1.Init.AddressingMode = I2C_ADDRESSINGMODE_7BIT;
  hi2c1.Init.DualAddressMode = I2C_DUALADDRESS_DISABLE;
  hi2c1.Init.OwnAddress2 = 0;
  hi2c1.Init.OwnAddress2Masks = I2C_OA2_NOMASK;
  hi2c1.Init.GeneralCallMode = I2C_GENERALCALL_DISABLE;
  hi2c1.Init.NoStretchMode = I2C_NOSTRETCH_DISABLE;
  if (HAL_I2C_Init(&hi2c1) != HAL_OK)
  {
    Error_Handler();
  }

  /** Configure Analogue filter
  */
  if (HAL_I2CEx_ConfigAnalogFilter(&hi2c1, I2C_ANALOGFILTER_ENABLE) != HAL_OK)
  {
    Error_Handler();
  }

  /** Configure Digital filter
  */
  if (HAL_I2CEx_ConfigDigitalFilter(&hi2c1, 0) != HAL_OK)
  {
    Error_Handler();
  }

}

static void MX_LTDC_Init(void)
{

  LTDC_LayerCfgTypeDef pLayerCfg = {0};

  hltdc.Instance = LTDC;
  hltdc.Init.HSPolarity = LTDC_HSPOLARITY_AL;
  hltdc.Init.VSPolarity = LTDC_VSPOLARITY_AL;
  hltdc.Init.DEPolarity = LTDC_DEPOLARITY_AL;
  hltdc.Init.PCPolarity = LTDC_PCPOLARITY_IPC;
  hltdc.Init.HorizontalSync = 40;
  hltdc.Init.VerticalSync = 9;
  hltdc.Init.AccumulatedHBP = 53;
  hltdc.Init.AccumulatedVBP = 11;
  hltdc.Init.AccumulatedActiveW = 533;
  hltdc.Init.AccumulatedActiveH = 283;
  hltdc.Init.TotalWidth = 565;
  hltdc.Init.TotalHeigh = 285;
  hltdc.Init.Backcolor.Blue = 0;
  hltdc.Init.Backcolor.Green = 0;
  hltdc.Init.Backcolor.Red = 0;
  if (HAL_LTDC_Init(&hltdc) != HAL_OK)
  {
    Error_Handler();
  }
  pLayerCfg.WindowX0 = 0;
  pLayerCfg.WindowX1 = 480;
  pLayerCfg.WindowY0 = 0;
  pLayerCfg.WindowY1 = 272;
  pLayerCfg.PixelFormat = LTDC_PIXEL_FORMAT_RGB565;
  pLayerCfg.Alpha = 255;
  pLayerCfg.Alpha0 = 0;
  pLayerCfg.BlendingFactor1 = LTDC_BLENDING_FACTOR1_PAxCA;
  pLayerCfg.BlendingFactor2 = LTDC_BLENDING_FACTOR2_PAxCA;
  pLayerCfg.FBStartAdress = 0xC0000000;
  pLayerCfg.ImageWidth = 480;
  pLayerCfg.ImageHeight = 272;
  pLayerCfg.Backcolor.Blue = 0;
  pLayerCfg.Backcolor.Green = 0;
  pLayerCfg.Backcolor.Red = 0;
  if (HAL_LTDC_ConfigLayer(&hltdc, &pLayerCfg, 0) != HAL_OK)
  {
    Error_Handler();
  }

}

static void MX_SDMMC1_SD_Init(void)
{

  hsd1.Instance = SDMMC1;
  hsd1.Init.ClockEdge = SDMMC_CLOCK_EDGE_RISING;
  hsd1.Init.ClockBypass = SDMMC_CLOCK_BYPASS_DISABLE;
  hsd1.Init.ClockPowerSave = SDMMC_CLOCK_POWER_SAVE_DISABLE;
  hsd1.Init.BusWide = SDMMC_BUS_WIDE_1B;
  hsd1.Init.HardwareFlowControl = SDMMC_HARDWARE_FLOW_CONTROL_DISABLE;
  hsd1.Init.ClockDiv = 0;

}

static void MX_USART6_UART_Init(void)
{

  huart6.Instance = USART6;
  huart6.Init.BaudRate = 115200;
  huart6.Init.WordLength = UART_WORDLENGTH_8B;
  huart6.Init.StopBits = UART_STOPBITS_1;
  huart6.Init.Parity = UART_PARITY_NONE;
  huart6.Init.Mode = UART_MODE_TX_RX;
  huart6.Init.HwFlowCtl = UART_HWCONTROL_NONE;
  huart6.Init.OverSampling = UART_OVERSAMPLING_16;
  huart6.Init.OneBitSampling = UART_ONE_BIT_SAMPLE_DISABLE;
  huart6.AdvancedInit.AdvFeatureInit = UART_ADVFEATURE_NO_INIT;
  if (HAL_UART_Init(&huart6) != HAL_OK)
  {
    Error_Handler();
  }

}

/* FMC initialization function */
static void MX_FMC_Init(void)
{

  FMC_SDRAM_TimingTypeDef SdramTiming = {0};

  /** Perform the SDRAM1 memory initialization sequence
  */
  hsdram1.Instance = FMC_SDRAM_DEVICE;
  /* hsdram1.Init */
  hsdram1.Init.SDBank = FMC_SDRAM_BANK1;
  hsdram1.Init.ColumnBitsNumber = FMC_SDRAM_COLUMN_BITS_NUM_8;
  hsdram1.Init.RowBitsNumber = FMC_SDRAM_ROW_BITS_NUM_12;
  hsdram1.Init.MemoryDataWidth = FMC_SDRAM_MEM_BUS_WIDTH_16;
  hsdram1.Init.InternalBankNumber = FMC_SDRAM_INTERN_BANKS_NUM_4;
  hsdram1.Init.CASLatency = FMC_SDRAM_CAS_LATENCY_3;
  hsdram1.Init.WriteProtection = FMC_SDRAM_WRITE_PROTECTION_DISABLE;
  hsdram1.Init.SDClockPeriod = FMC_SDRAM_CLOCK_PERIOD_2;
  hsdram1.Init.ReadBurst = FMC_SDRAM_RBURST_DISABLE;
  hsdram1.Init.ReadPipeDelay = FMC_SDRAM_RPIPE_DELAY_0;
  /* SdramTiming */
  SdramTiming.LoadToActiveDelay = 2;
  SdramTiming.ExitSelfRefreshDelay = 7;
  SdramTiming.SelfRefreshTime = 4;
  SdramTiming.RowCycleDelay = 7;
  SdramTiming.WriteRecoveryTime = 3;
  SdramTiming.RPDelay = 2;
  SdramTiming.RCDDelay = 2;

  if (HAL_SDRAM_Init(&hsdram1, &SdramTiming) != HAL_OK)
  {
    Error_Handler( );
  }

}

static void MX_GPIO_Init(void)
{
  GPIO_InitTypeDef GPIO_InitStruct = {0};

  /* GPIO Ports Clock Enable */
  __HAL_RCC_GPIOE_CLK_ENABLE();
  __HAL_RCC_GPIOG_CLK_ENABLE();
  __HAL_RCC_GPIOB_CLK_ENABLE();
  __HAL_RCC_GPIOD_CLK_ENABLE();
  __HAL_RCC_GPIOC_CLK_ENABLE();
  __HAL_RCC_GPIOA_CLK_ENABLE();
  __HAL_RCC_GPIOJ_CLK_ENABLE();
  __HAL_RCC_GPIOI_CLK_ENABLE();
  __HAL_RCC_GPIOK_CLK_ENABLE();
  __HAL_RCC_GPIOF_CLK_ENABLE();
  __HAL_RCC_GPIOH_CLK_ENABLE();

  /*Configure GPIO pin Output Level */
  HAL_GPIO_WritePin(OTG_FS_PowerSwitchOn_GPIO_Port, OTG_FS_PowerSwitchOn_Pin, GPIO_PIN_SET);

  /*Configure GPIO pin Output Level */
  HAL_GPIO_WritePin(GPIOI, ARDUINO_D7_Pin|ARDUINO_D8_Pin|LED_Pin|LCD_DISP_Pin, GPIO_PIN_RESET);

  /*Configure GPIO pin Output Level */
  HAL_GPIO_WritePin(LCD_BL_CTRL_GPIO_Port, LCD_BL_CTRL_Pin, GPIO_PIN_RESET);

  /*Configure GPIO pin Output Level */
  HAL_GPIO_WritePin(DCMI_PWR_EN_GPIO_Port, DCMI_PWR_EN_Pin, GPIO_PIN_RESET);

  /*Configure GPIO pin Output Level */
  HAL_GPIO_WritePin(GPIOG, ARDUINO_D4_Pin|ARDUINO_D2_Pin|EXT_RST_Pin, GPIO_PIN_RESET);

  /*Configure GPIO pin : OTG_HS_OverCurrent_Pin */
  GPIO_InitStruct.Pin = OTG_HS_OverCurrent_Pin;
  GPIO_InitStruct.Mode = GPIO_MODE_INPUT;
  GPIO_InitStruct.Pull = GPIO_NOPULL;
  HAL_GPIO_Init(OTG_HS_OverCurrent_GPIO_Port, &GPIO_InitStruct);

  /*Configure GPIO pin : QSPI_D2_Pin */
  GPIO_InitStruct.Pin = QSPI_D2_Pin;
  GPIO_InitStruct.Mode = GPIO_MODE_AF_PP;
  GPIO_InitStruct.Pull = GPIO_NOPULL;
  GPIO_InitStruct.Speed = GPIO_SPEED_FREQ_VERY_HIGH;
  GPIO_InitStruct.Alternate = GPIO_AF9_QUADSPI;
  HAL_GPIO_Init(QSPI_D2_GPIO_Port, &GPIO_InitStruct);

  /*Configure GPIO pins : ULPI_D7_Pin ULPI_D6_Pin ULPI_D5_Pin ULPI_D3_Pin
                           ULPI_D2_Pin ULPI_D1_Pin ULPI_D4_Pin */
  GPIO_InitStruct.Pin = ULPI_D7_Pin|ULPI_D6_Pin|ULPI_D5_Pin|ULPI_D3_Pin
                          |ULPI_D2_Pin|ULPI_D1_Pin|ULPI_D4_Pin;
  GPIO_InitStruct.Mode = GPIO_MODE_AF_PP;
  GPIO_InitStruct.Pull = GPIO_NOPULL;
  GPIO_InitStruct.Speed = GPIO_SPEED_FREQ_VERY_HIGH;
  GPIO_InitStruct.Alternate = GPIO_AF10_OTG_HS;
  HAL_GPIO_Init(GPIOB, &GPIO_InitStruct);

  /*Configure GPIO pin : ARDUINO_PWM_D3_Pin */
  GPIO_InitStruct.Pin = ARDUINO_PWM_D3_Pin;
  GPIO_InitStruct.Mode = GPIO_MODE_AF_PP;
  GPIO_InitStruct.Pull = GPIO_NOPULL;
  GPIO_InitStruct.Speed = GPIO_SPEED_FREQ_LOW;
  GPIO_InitStruct.Alternate = GPIO_AF2_TIM3;
  HAL_GPIO_Init(ARDUINO_PWM_D3_GPIO_Port, &GPIO_InitStruct);

  /*Configure GPIO pin : SPDIF_RX0_Pin */
  GPIO_InitStruct.Pin = SPDIF_RX0_Pin;
  GPIO_InitStruct.Mode = GPIO_MODE_AF_PP;
  GPIO_InitStruct.Pull = GPIO_NOPULL;
  GPIO_InitStruct.Speed = GPIO_SPEED_FREQ_LOW;
  GPIO_InitStruct.Alternate = GPIO_AF8_SPDIFRX;
  HAL_GPIO_Init(SPDIF_RX0_GPIO_Port, &GPIO_InitStruct);

  /*Configure GPIO pin : ARDUINO_PWM_D9_Pin */
  GPIO_InitStruct.Pin = ARDUINO_PWM_D9_Pin;
  GPIO_InitStruct.Mode = GPIO_MODE_AF_PP;
  GPIO_InitStruct.Pull = GPIO_NOPULL;
  GPIO_InitStruct.Speed = GPIO_SPEED_FREQ_LOW;
  GPIO_InitStruct.Alternate = GPIO_AF1_TIM2;
  HAL_GPIO_Init(ARDUINO_PWM_D9_GPIO_Port, &GPIO_InitStruct);

  /*Configure GPIO pins : DCMI_D6_Pin DCMI_D7_Pin */
  GPIO_InitStruct.Pin = DCMI_D6_Pin|DCMI_D7_Pin;
  GPIO_InitStruct.Mode = GPIO_MODE_AF_PP;
  GPIO_InitStruct.Pull = GPIO_NOPULL;
  GPIO_InitStruct.Speed = GPIO_SPEED_FREQ_LOW;
  GPIO_InitStruct.Alternate = GPIO_AF13_DCMI;
  HAL_GPIO_Init(GPIOE, &GPIO_InitStruct);

  /*Configure GPIO pin : VCP_RX_Pin */
  GPIO_InitStruct.Pin = VCP_RX_Pin;
  GPIO_InitStruct.Mode = GPIO_MODE_AF_PP;
  GPIO_InitStruct.Pull = GPIO_NOPULL;
  GPIO_InitStruct.Speed = GPIO_SPEED_FREQ_LOW;
  GPIO_InitStruct.Alternate = GPIO_AF7_USART1;
  HAL_GPIO_Init(VCP_RX_GPIO_Port, &GPIO_InitStruct);

  /*Configure GPIO pin : QSPI_NCS_Pin */
  GPIO_InitStruct.Pin = QSPI_NCS_Pin;
  GPIO_InitStruct.Mode = GPIO_MODE_AF_PP;
  GPIO_InitStruct.Pull = GPIO_NOPULL;
  GPIO_InitStruct.Speed = GPIO_SPEED_FREQ_VERY_HIGH;
  GPIO_InitStruct.Alternate = GPIO_AF10_QUADSPI;
  HAL_GPIO_Init(QSPI_NCS_GPIO_Port, &GPIO_InitStruct);

  /*Configure GPIO pin : OTG_FS_VBUS_Pin */
  GPIO_InitStruct.Pin = OTG_FS_VBUS_Pin;
  GPIO_InitStruct.Mode = GPIO_MODE_INPUT;
  GPIO_InitStruct.Pull = GPIO_NOPULL;
  HAL_GPIO_Init(OTG_FS_VBUS_GPIO_Port, &GPIO_InitStruct);

  /*Configure GPIO pin : Audio_INT_Pin */
  GPIO_InitStruct.Pin = Audio_INT_Pin;
  GPIO_InitStruct.Mode = GPIO_MODE_EVT_RISING;
  GPIO_InitStruct.Pull = GPIO_NOPULL;
  HAL_GPIO_Init(Audio_INT_GPIO_Port, &GPIO_InitStruct);

  /*Configure GPIO pins : OTG_FS_P_Pin OTG_FS_N_Pin OTG_FS_ID_Pin */
  GPIO_InitStruct.Pin = OTG_FS_P_Pin|OTG_FS_N_Pin|OTG_FS_ID_Pin;
  GPIO_InitStruct.Mode = GPIO_MODE_AF_PP;
  GPIO_InitStruct.Pull = GPIO_NOPULL;
  GPIO_InitStruct.Speed = GPIO_SPEED_FREQ_VERY_HIGH;
  GPIO_InitStruct.Alternate = GPIO_AF10_OTG_FS;
  HAL_GPIO_Init(GPIOA, &GPIO_InitStruct);

  /*Configure GPIO pins : SAI2_MCLKA_Pin SAI2_SCKA_Pin SAI2_FSA_Pin SAI2_SDA_Pin */
  GPIO_InitStruct.Pin = SAI2_MCLKA_Pin|SAI2_SCKA_Pin|SAI2_FSA_Pin|SAI2_SDA_Pin;
  GPIO_InitStruct.Mode = GPIO_MODE_AF_PP;
  GPIO_InitStruct.Pull = GPIO_NOPULL;
  GPIO_InitStruct.Speed = GPIO_SPEED_FREQ_LOW;
  GPIO_InitStruct.Alternate = GPIO_AF10_SAI2;
  HAL_GPIO_Init(GPIOI, &GPIO_InitStruct);

  /*Configure GPIO pin : SAI2_SDB_Pin */
  GPIO_InitStruct.Pin = SAI2_SDB_Pin;
  GPIO_InitStruct.Mode = GPIO_MODE_AF_PP;
  GPIO_InitStruct.Pull = GPIO_NOPULL;
  GPIO_InitStruct.Speed = GPIO_SPEED_FREQ_LOW;
  GPIO_InitStruct.Alternate = GPIO_AF10_SAI2;
  HAL_GPIO_Init(SAI2_SDB_GPIO_Port, &GPIO_InitStruct);

  /*Configure GPIO pin : OTG_FS_PowerSwitchOn_Pin */
  GPIO_InitStruct.Pin = OTG_FS_PowerSwitchOn_Pin;
  GPIO_InitStruct.Mode = GPIO_MODE_OUTPUT_PP;
  GPIO_InitStruct.Pull = GPIO_NOPULL;
  GPIO_InitStruct.Speed = GPIO_SPEED_FREQ_LOW;
  HAL_GPIO_Init(OTG_FS_PowerSwitchOn_GPIO_Port, &GPIO_InitStruct);

  /*Configure GPIO pin : DCMI_D5_Pin */
  GPIO_InitStruct.Pin = DCMI_D5_Pin;
  GPIO_InitStruct.Mode = GPIO_MODE_AF_PP;
  GPIO_InitStruct.Pull = GPIO_NOPULL;
  GPIO_InitStruct.Speed = GPIO_SPEED_FREQ_LOW;
  GPIO_InitStruct.Alternate = GPIO_AF13_DCMI;
  HAL_GPIO_Init(DCMI_D5_GPIO_Port, &GPIO_InitStruct);

  /*Configure GPIO pins : ARDUINO_D7_Pin ARDUINO_D8_Pin LED_Pin LCD_DISP_Pin */
  GPIO_InitStruct.Pin = ARDUINO_D7_Pin|ARDUINO_D8_Pin|LED_Pin|LCD_DISP_Pin;
  GPIO_InitStruct.Mode = GPIO_MODE_OUTPUT_PP;
  GPIO_InitStruct.Pull = GPIO_NOPULL;
  GPIO_InitStruct.Speed = GPIO_SPEED_FREQ_LOW;
  HAL_GPIO_Init(GPIOI, &GPIO_InitStruct);

  /*Configure GPIO pin : uSD_Detect_Pin */
  GPIO_InitStruct.Pin = uSD_Detect_Pin;
  GPIO_InitStruct.Mode = GPIO_MODE_INPUT;
  GPIO_InitStruct.Pull = GPIO_NOPULL;
  HAL_GPIO_Init(uSD_Detect_GPIO_Port, &GPIO_InitStruct);

  /*Configure GPIO pin : LCD_BL_CTRL_Pin */
  GPIO_InitStruct.Pin = LCD_BL_CTRL_Pin;
  GPIO_InitStruct.Mode = GPIO_MODE_OUTPUT_PP;
  GPIO_InitStruct.Pull = GPIO_NOPULL;
  GPIO_InitStruct.Speed = GPIO_SPEED_FREQ_LOW;
  HAL_GPIO_Init(LCD_BL_CTRL_GPIO_Port, &GPIO_InitStruct);

  /*Configure GPIO pin : DCMI_VSYNC_Pin */
  GPIO_InitStruct.Pin = DCMI_VSYNC_Pin;
  GPIO_InitStruct.Mode = GPIO_MODE_AF_PP;
  GPIO_InitStruct.Pull = GPIO_NOPULL;
  GPIO_InitStruct.Speed = GPIO_SPEED_FREQ_LOW;
  GPIO_InitStruct.Alternate = GPIO_AF13_DCMI;
  HAL_GPIO_Init(DCMI_VSYNC_GPIO_Port, &GPIO_InitStruct);

  /*Configure GPIO pin : OTG_FS_OverCurrent_Pin */
  GPIO_InitStruct.Pin = OTG_FS_OverCurrent_Pin;
  GPIO_InitStruct.Mode = GPIO_MODE_INPUT;
  GPIO_InitStruct.Pull = GPIO_NOPULL;
  HAL_GPIO_Init(OTG_FS_OverCurrent_GPIO_Port, &GPIO_InitStruct);

  /*Configure GPIO pins : TP3_Pin NC2_Pin */
  GPIO_InitStruct.Pin = TP3_Pin|NC2_Pin;
  GPIO_InitStruct.Mode = GPIO_MODE_INPUT;
  GPIO_InitStruct.Pull = GPIO_NOPULL;
  HAL_GPIO_Init(GPIOH, &GPIO_InitStruct);

  /*Configure GPIO pin : DCMI_PWR_EN_Pin */
  GPIO_InitStruct.Pin = DCMI_PWR_EN_Pin;
  GPIO_InitStruct.Mode = GPIO_MODE_OUTPUT_PP;
  GPIO_InitStruct.Pull = GPIO_NOPULL;
  GPIO_InitStruct.Speed = GPIO_SPEED_FREQ_LOW;
  HAL_GPIO_Init(DCMI_PWR_EN_GPIO_Port, &GPIO_InitStruct);

  /*Configure GPIO pins : DCMI_D4_Pin DCMI_D3_Pin DCMI_D0_Pin DCMI_D2_Pin
                           DCMI_D1_Pin */
  GPIO_InitStruct.Pin = DCMI_D4_Pin|DCMI_D3_Pin|DCMI_D0_Pin|DCMI_D2_Pin
                          |DCMI_D1_Pin;
  GPIO_InitStruct.Mode = GPIO_MODE_AF_PP;
  GPIO_InitStruct.Pull = GPIO_NOPULL;
  GPIO_InitStruct.Speed = GPIO_SPEED_FREQ_LOW;
  GPIO_InitStruct.Alternate = GPIO_AF13_DCMI;
  HAL_GPIO_Init(GPIOH, &GPIO_InitStruct);

  /*Configure GPIO pin : ARDUINO_PWM_CS_D5_Pin */
  GPIO_InitStruct.Pin = ARDUINO_PWM_CS_D5_Pin;
  GPIO_InitStruct.Mode = GPIO_MODE_AF_PP;
  GPIO_InitStruct.Pull = GPIO_NOPULL;
  GPIO_InitStruct.Speed = GPIO_SPEED_FREQ_LOW;
  GPIO_InitStruct.Alternate = GPIO_AF2_TIM5;
  HAL_GPIO_Init(ARDUINO_PWM_CS_D5_GPIO_Port, &GPIO_InitStruct);

  /*Configure GPIO pin : VCP_TX_Pin */
  GPIO_InitStruct.Pin = VCP_TX_Pin;
  GPIO_InitStruct.Mode = GPIO_MODE_AF_PP;
  GPIO_InitStruct.Pull = GPIO_NOPULL;
  GPIO_InitStruct.Speed = GPIO_SPEED_FREQ_LOW;
  GPIO_InitStruct.Alternate = GPIO_AF7_USART1;
  HAL_GPIO_Init(VCP_TX_GPIO_Port, &GPIO_InitStruct);

  /*Configure GPIO pin : ARDUINO_PWM_D10_Pin */
  GPIO_InitStruct.Pin = ARDUINO_PWM_D10_Pin;
  GPIO_InitStruct.Mode = GPIO_MODE_AF_PP;
  GPIO_InitStruct.Pull = GPIO_NOPULL;
  GPIO_InitStruct.Speed = GPIO_SPEED_FREQ_LOW;
  GPIO_InitStruct.Alternate = GPIO_AF1_TIM1;
  HAL_GPIO_Init(ARDUINO_PWM_D10_GPIO_Port, &GPIO_InitStruct);

  /*Configure GPIO pin : LCD_INT_Pin */
  GPIO_InitStruct.Pin = LCD_INT_Pin;
  GPIO_InitStruct.Mode = GPIO_MODE_EVT_RISING;
  GPIO_InitStruct.Pull = GPIO_NOPULL;
  HAL_GPIO_Init(LCD_INT_GPIO_Port, &GPIO_InitStruct);

  /*Configure GPIO pin : ULPI_NXT_Pin */
  GPIO_InitStruct.Pin = ULPI_NXT_Pin;
  GPIO_InitStruct.Mode = GPIO_MODE_AF_PP;
  GPIO_InitStruct.Pull = GPIO_NOPULL;
  GPIO_InitStruct.Speed = GPIO_SPEED_FREQ_VERY_HIGH;
  GPIO_InitStruct.Alternate = GPIO_AF10_OTG_HS;
  HAL_GPIO_Init(ULPI_NXT_GPIO_Port, &GPIO_InitStruct);

  /*Configure GPIO pins : ARDUINO_D4_Pin ARDUINO_D2_Pin EXT_RST_Pin */
  GPIO_InitStruct.Pin = ARDUINO_D4_Pin|ARDUINO_D2_Pin|EXT_RST_Pin;
  GPIO_InitStruct.Mode = GPIO_MODE_OUTPUT_PP;
  GPIO_InitStruct.Pull = GPIO_NOPULL;
  GPIO_InitStruct.Speed = GPIO_SPEED_FREQ_LOW;
  HAL_GPIO_Init(GPIOG, &GPIO_InitStruct);

  /*Configure GPIO pins : ARDUINO_A4_Pin ARDUINO_A5_Pin ARDUINO_A1_Pin ARDUINO_A2_Pin
                           ARDUINO_A3_Pin */
  GPIO_InitStruct.Pin = ARDUINO_A4_Pin|ARDUINO_A5_Pin|ARDUINO_A1_Pin|ARDUINO_A2_Pin
                          |ARDUINO_A3_Pin;
  GPIO_InitStruct.Mode = GPIO_MODE_ANALOG;
  GPIO_InitStruct.Pull = GPIO_NOPULL;
  HAL_GPIO_Init(GPIOF, &GPIO_InitStruct);

  /*Configure GPIO pins : ULPI_STP_Pin ULPI_DIR_Pin */
  GPIO_InitStruct.Pin = ULPI_STP_Pin|ULPI_DIR_Pin;
  GPIO_InitStruct.Mode = GPIO_MODE_AF_PP;
  GPIO_InitStruct.Pull = GPIO_NOPULL;
  GPIO_InitStruct.Speed = GPIO_SPEED_FREQ_VERY_HIGH;
  GPIO_InitStruct.Alternate = GPIO_AF10_OTG_HS;
  HAL_GPIO_Init(GPIOC, &GPIO_InitStruct);

  /*Configure GPIO pin : PB2 */
  GPIO_InitStruct.Pin = GPIO_PIN_2;
  GPIO_InitStruct.Mode = GPIO_MODE_AF_PP;
  GPIO_InitStruct.Pull = GPIO_NOPULL;
  GPIO_InitStruct.Speed = GPIO_SPEED_FREQ_VERY_HIGH;
  GPIO_InitStruct.Alternate = GPIO_AF9_QUADSPI;
  HAL_GPIO_Init(GPIOB, &GPIO_InitStruct);

  /*Configure GPIO pins : QSPI_D1_Pin QSPI_D3_Pin QSPI_D0_Pin */
  GPIO_InitStruct.Pin = QSPI_D1_Pin|QSPI_D3_Pin|QSPI_D0_Pin;
  GPIO_InitStruct.Mode = GPIO_MODE_AF_PP;
  GPIO_InitStruct.Pull = GPIO_NOPULL;
  GPIO_InitStruct.Speed = GPIO_SPEED_FREQ_VERY_HIGH;
  GPIO_InitStruct.Alternate = GPIO_AF9_QUADSPI;
  HAL_GPIO_Init(GPIOD, &GPIO_InitStruct);

  /*Configure GPIO pin : RMII_RXER_Pin */
  GPIO_InitStruct.Pin = RMII_RXER_Pin;
  GPIO_InitStruct.Mode = GPIO_MODE_INPUT;
  GPIO_InitStruct.Pull = GPIO_NOPULL;
  HAL_GPIO_Init(RMII_RXER_GPIO_Port, &GPIO_InitStruct);

  /*Configure GPIO pin : ARDUINO_A0_Pin */
  GPIO_InitStruct.Pin = ARDUINO_A0_Pin;
  GPIO_InitStruct.Mode = GPIO_MODE_ANALOG;
  GPIO_InitStruct.Pull = GPIO_NOPULL;
  HAL_GPIO_Init(ARDUINO_A0_GPIO_Port, &GPIO_InitStruct);

  /*Configure GPIO pins : DCMI_HSYNC_Pin PA6 */
  GPIO_InitStruct.Pin = DCMI_HSYNC_Pin|GPIO_PIN_6;
  GPIO_InitStruct.Mode = GPIO_MODE_AF_PP;
  GPIO_InitStruct.Pull = GPIO_NOPULL;
  GPIO_InitStruct.Speed = GPIO_SPEED_FREQ_LOW;
  GPIO_InitStruct.Alternate = GPIO_AF13_DCMI;
  HAL_GPIO_Init(GPIOA, &GPIO_InitStruct);

  /*Configure GPIO pins : LCD_SCL_Pin LCD_SDA_Pin */
  GPIO_InitStruct.Pin = LCD_SCL_Pin|LCD_SDA_Pin;
  GPIO_InitStruct.Mode = GPIO_MODE_AF_OD;
  GPIO_InitStruct.Pull = GPIO_NOPULL;
  GPIO_InitStruct.Speed = GPIO_SPEED_FREQ_VERY_HIGH;
  GPIO_InitStruct.Alternate = GPIO_AF4_I2C3;
  HAL_GPIO_Init(GPIOH, &GPIO_InitStruct);

  /*Configure GPIO pins : ULPI_CLK_Pin ULPI_D0_Pin */
  GPIO_InitStruct.Pin = ULPI_CLK_Pin|ULPI_D0_Pin;
  GPIO_InitStruct.Mode = GPIO_MODE_AF_PP;
  GPIO_InitStruct.Pull = GPIO_NOPULL;
  GPIO_InitStruct.Speed = GPIO_SPEED_FREQ_VERY_HIGH;
  GPIO_InitStruct.Alternate = GPIO_AF10_OTG_HS;
  HAL_GPIO_Init(GPIOA, &GPIO_InitStruct);

  /*Configure GPIO pin : ARDUINO_PWM_D6_Pin */
  GPIO_InitStruct.Pin = ARDUINO_PWM_D6_Pin;
  GPIO_InitStruct.Mode = GPIO_MODE_AF_PP;
  GPIO_InitStruct.Pull = GPIO_NOPULL;
  GPIO_InitStruct.Speed = GPIO_SPEED_FREQ_LOW;
  GPIO_InitStruct.Alternate = GPIO_AF9_TIM12;
  HAL_GPIO_Init(ARDUINO_PWM_D6_GPIO_Port, &GPIO_InitStruct);

  /*Configure GPIO pins : ARDUINO_MISO_D12_Pin ARDUINO_MOSI_PWM_D11_Pin */
  GPIO_InitStruct.Pin = ARDUINO_MISO_D12_Pin|ARDUINO_MOSI_PWM_D11_Pin;
  GPIO_InitStruct.Mode = GPIO_MODE_AF_PP;
  GPIO_InitStruct.Pull = GPIO_NOPULL;
  GPIO_InitStruct.Speed = GPIO_SPEED_FREQ_LOW;
  GPIO_InitStruct.Alternate = GPIO_AF5_SPI2;
  HAL_GPIO_Init(GPIOB, &GPIO_InitStruct);

}

/* USER CODE BEGIN 4 */
/* LwIP seri port (SLIP) baglantisi - projede kullanilmiyor.
 * CubeMX slipif.c'yi her zaman projeye ekler; bos fonksiyonlarini yalnizca
 * eski Keil derleyicisi (__CC_ARM) icin lwip.c'de uretir. ArmClang (V6) icin
 * baglayici hatasi (L6218E sio_open/sio_send/sio_tryread) olmamasi icin burada. */
sio_fd_t sio_open(u8_t devnum)                         { (void)devnum; return NULL; }
void     sio_send(u8_t c, sio_fd_t fd)                  { (void)c; (void)fd; }
u32_t    sio_read(sio_fd_t fd, u8_t *data, u32_t len)   { (void)fd; (void)data; (void)len; return 0; }
u32_t    sio_tryread(sio_fd_t fd, u8_t *data, u32_t len){ (void)fd; (void)data; (void)len; return 0; }

static uint8_t Button_IsPressed(void)
{
  return (BSP_PB_GetState(BUTTON_WAKEUP) == GPIO_PIN_SET);
}

static void Draw_StartupScreen(void)
{
  Exp_State es = Exp_GetStatus()->state;
  UI_SetRecording(LogCtrl_IsActive());
  UI_SetRecLocked((es == EXP_RUNNING || es == EXP_PAUSED) ? 1U : 0U);
  UI_SetButtonLabel(UI_BTN_EXP, "DENEY", (es == EXP_IDLE) ? "menu" : "izle", UI_STYLE_ACCENT);
  UI_DrawFrame();
  rtc_last_sec = 0xFF;        /* saat bir sonraki dongude yeniden cizilsin */
  UI_UpdateSensors();
  UI_UpdatePeltier(1);
  UI_UpdateSd();
  UI_UpdateExp(1);
  UI_UpdateNet(1);
  UI_DrawDoor(door_open);
}

/* Sabit noktali sayiyi metne cevirir (float printf gerektirmez).
 * scale = 10  -> 1 ondalik  (ornek 234  -> "23.4")
 * scale = 100 -> 2 ondalik  (ornek 2344 -> "23.44") */
static void Fmt_Fixed(char *buf, size_t n, int32_t v, int32_t scale)
{
  const char *sign = (v < 0) ? "-" : "";
  if (v < 0) v = -v;
  if (scale == 100)
  {
    snprintf(buf, n, "%s%ld.%02ld", sign, (long)(v / 100), (long)(v % 100));
  }
  else
  {
    snprintf(buf, n, "%s%ld.%ld", sign, (long)(v / 10), (long)(v % 10));
  }
}

static const char *Dht_Short(DHT22_Status st)
{
  switch (st)
  {
    case DHT22_OK:              return "OK ";
    case DHT22_ERR_NO_RESPONSE: return "YOK";
    case DHT22_ERR_TIMEOUT:     return "ZAM";
    case DHT22_ERR_CHECKSUM:    return "CRC";
    default:                    return "-- ";
  }
}

static const char *Ds_Short(DS18B20_StatusTypeDef st)
{
  switch (st)
  {
    case DS18B20_OK:            return "OK ";
    case DS18B20_ERR_NO_SENSOR: return "YOK";
    case DS18B20_ERR_CRC:       return "CRC";
    case DS18B20_ERR_POWERON:   return "85C";
    case DS18B20_ERROR:         return "HAT";
    default:                    return "-- ";
  }
}

/* DS18B20 kartinin durum seviyesi ve alt satiri */
static UI_Level Ds_Level(const DS18B20_HandleTypeDef *d, const char **sub, const char *ok_text)
{
  if (d->fault)
  {
    *sub = d->valid ? "ARIZA - eski deger" : "ARIZA - sensor yok";
    return UI_LEVEL_FAULT;
  }
  if (d->status == DS18B20_OK)
  {
    *sub = ok_text;
    return UI_LEVEL_OK;
  }
  if (!d->valid)
  {
    if (d->status == DS18B20_BUSY) { *sub = "olcum bekleniyor"; return UI_LEVEL_WARN; }
    *sub = "veri yok";
    return UI_LEVEL_FAULT;
  }
  *sub = "son gecerli deger";
  return UI_LEVEL_WARN;
}

static void UI_UpdateSensors(void)
{
  static const char *const ds_text[3] = { "ic sogutucu", "duvar yuzeyi", "dolap disi" };
  static const uint8_t     ds_card[3] = { UI_CARD_PELTIER, UI_CARD_WALL, UI_CARD_AMBIENT };
  char rh[24], st[8], h[12];
  UI_Level lv;
  const char *sub;

  /* DHT22: kabin havasi + nem */
  if (hdht22.fault)                                   lv = UI_LEVEL_FAULT;
  else if (hdht22.last_status == DHT22_OK ||
           hdht22.last_status == DHT22_ERR_TOO_SOON)  lv = UI_LEVEL_OK;
  else                                                lv = hdht22.valid ? UI_LEVEL_WARN : UI_LEVEL_FAULT;

  if (hdht22.valid)
  {
    Fmt_Fixed(h, sizeof(h), (int32_t)hdht22.humidity_x10, 10);
    snprintf(rh, sizeof(rh), "Nem %%%s", h);
  }
  else
  {
    snprintf(rh, sizeof(rh), "veri yok");
  }
  snprintf(st, sizeof(st), "%s", hdht22.fault ? "ARZ"
                                 : ((lv == UI_LEVEL_OK) ? "OK" : Dht_Short(hdht22.last_status)));
  UI_DrawSensor(UI_CARD_AIR, hdht22.valid, hdht22.temperature_x10, 1, st, lv, rh, 1);

  /* DS18B20'ler */
  for (uint8_t k = 0; k < 3U; k++)
  {
    DS18B20_HandleTypeDef *d = ds_list[k];
    lv = Ds_Level(d, &sub, ds_text[k]);
    snprintf(st, sizeof(st), "%s", d->fault ? "ARZ" : Ds_Short(d->status));
    UI_DrawSensor(ds_card[k], d->valid, d->temperature_x100, 2, st, lv, sub, 0);
  }
}

/* Peltier paneli: force=0 iken yalnizca komut veya baglanti degistiyse cizer */
static void UI_UpdatePeltier(uint8_t force)
{
  static int16_t           last_cmd  = 0x7FFF;
  static Peltier_LinkState last_link = (Peltier_LinkState)0xFF;
  const Peltier_Status    *ps = Peltier_GetStatus();

  if (force || ps->command != last_cmd || ps->link != last_link)
  {
    last_cmd  = ps->command;
    last_link = ps->link;
    UI_DrawPeltier(ps->command, Peltier_IsLinkOk(), Peltier_LinkShort(ps->link));
  }
}

/* SD paneli: kart, dosya, kayit sayisi, boyut, bos alan, hata */
static void UI_UpdateSd(void)
{
  UI_SdInfo sd;
  const SdLog_Info *li = SdLog_GetInfo();
  memset(&sd, 0, sizeof(sd));
  sd.present   = (BSP_PlatformIsDetected() == SD_PRESENT) ? 1U : 0U;
  sd.logging   = LogCtrl_IsActive();
  sd.file      = SdLog_FileName();
  sd.records   = li->records;
  sd.size_kb   = li->size_kb;
  sd.last_write= (li->last_write[0] != '-') ? li->last_write : NULL;
  sd.free_mb   = li->free_mb;
  sd.errors    = li->errors;
  sd.eeprom_ok = LogCtrl_EepromOk();
  sd.resumed   = LogCtrl_WasResumed();
  UI_DrawSd(&sd);
}

/* screen.c geri cagirmalari */
void App_RedrawMain(void)
{
  Draw_StartupScreen();
}

void App_RecordingChanged(void)
{
  Exp_State es = Exp_GetStatus()->state;
  UI_SetRecording(LogCtrl_IsActive());
  UI_SetRecLocked((es == EXP_RUNNING || es == EXP_PAUSED) ? 1U : 0U);
  if (Screen_Current() == SCREEN_MAIN)
  {
    UI_DrawButton(UI_BTN_REC, 0U);
    UI_UpdateSd();
  }
}

/* Adafruit IO'ya gidecek anlik degerler (gecersiz sensorler gonderilmez) */
static void Aio_Fill(Aio_Data *a)
{
  const Exp_Status *e = Exp_GetStatus();
  char k[20];

  memset(a, 0, sizeof(*a));
  a->air_ok   = (hdht22.valid && hdht22.last_status == DHT22_OK) ? 1U : 0U;
  a->air_x10  = hdht22.temperature_x10;
  a->rh_ok    = a->air_ok;
  a->rh_x10   = hdht22.humidity_x10;
  a->pel_ok   = (hds_heatsink.status == DS18B20_OK) ? 1U : 0U;
  a->pel_x100 = hds_heatsink.temperature_x100;
  a->wall_ok  = (hds_wall.status == DS18B20_OK) ? 1U : 0U;
  a->wall_x100 = hds_wall.temperature_x100;
  a->amb_ok   = (hds_ambient.status == DS18B20_OK) ? 1U : 0U;
  a->amb_x100 = hds_ambient.temperature_x100;
  a->u_cmd    = Peltier_GetCommand();
  a->safety   = (uint8_t)e->safety;

  /* SD kart: durum|dosya|kayit|hata|bos MB|dosya KB (web sayfasi ayristirir) */
  {
    static const char *const sdn[] = { "KART YOK", "HAZIR", "KAYITTA", "HATA", "SAAT YOK" };
    const SdLog_Info *s = SdLog_GetInfo();
    snprintf(a->sd, sizeof(a->sd), "%s|%s|%lu|%lu|%lu|%lu",
             ((unsigned)s->state < 5U) ? sdn[s->state] : "?", s->file,
             (unsigned long)s->records, (unsigned long)s->errors,
             (unsigned long)s->free_mb, (unsigned long)s->size_kb);
  }

  if (e->state == EXP_IDLE)
  {
    snprintf(a->status, sizeof(a->status), door_open ? "BOSTA | KAPAK ACIK" : "BOSTA");
    return;
  }
  a->sp_ok  = (e->closed && e->state != EXP_DONE) ? 1U : 0U;
  a->sp_x10 = e->sp_x10;

  Exp_FormatDuration(k, sizeof(k), (e->state == EXP_DONE) ? 0U : e->total_left_s);
  if (e->safety != EXP_SAFE_OK)
    snprintf(a->status, sizeof(a->status), "%s | GUVENLIK: %s", Exp_ProcName(e->proc), Exp_SafetyName(e->safety));
  else if (e->limit != 0U && e->state == EXP_RUNNING)
    snprintf(a->status, sizeof(a->status), "%s | %s SINIRLI | kalan %s", Exp_ProcName(e->proc),
             (e->limit == 1U) ? "ISITMA" : "SOGUTMA", k);
  else if (e->full)
    snprintf(a->status, sizeof(a->status), "%s [%u/%u] | %s | kalan %s", Exp_ProcName(e->proc),
             e->stage + 1U, e->stages, Exp_StateName(e->state), k);
  else
    snprintf(a->status, sizeof(a->status), "%s | %s | kalan %s", Exp_ProcName(e->proc), Exp_StateName(e->state), k);
  if (door_open)
  {
    size_t n = strlen(a->status);
    snprintf(a->status + n, sizeof(a->status) - n, " | KAPAK ACIK");
  }
}

/* Ana ekran basligi: ag ve sunucu durumu. Metin degismedikce yeniden cizilmez. */
static void UI_UpdateNet(uint8_t force)
{
  static char last1[40], last2[40];
  static UI_Tone lt1, lt2;
  const Net_Status *n = Net_GetStatus();
  char l1[40], l2[40];
  UI_Tone t1, t2;

  switch (n->link)
  {
    case NET_LINK_DOWN:
      snprintf(l1, sizeof(l1), "AG: ETHERNET KABLOSU YOK");
      t1 = UI_TONE_ERR;
      break;
    case NET_LINK_NOIP:
      snprintf(l1, sizeof(l1), "AG: IP BEKLENIYOR (DHCP)");
      t1 = UI_TONE_WARN;
      break;
    default:
      snprintf(l1, sizeof(l1), "IP: %u.%u.%u.%u", n->ip[0], n->ip[1], n->ip[2], n->ip[3]);
      t1 = UI_TONE_OK;
      break;
  }

  if (n->srv == NET_SRV_OFF)
  {
    snprintf(l2, sizeof(l2), "%s: KAPALI", NET_SERVER_NAME);
    t2 = UI_TONE_MUTED;
  }
  else if (n->link != NET_LINK_UP)
  {
    snprintf(l2, sizeof(l2), "%s: AG BEKLENIYOR", NET_SERVER_NAME);
    t2 = UI_TONE_MUTED;
  }
  else if (n->srv == NET_SRV_CONNECTING)
  {
    snprintf(l2, sizeof(l2), "%s: BAGLANIYOR", NET_SERVER_NAME);
    t2 = UI_TONE_WARN;
  }
  else if (n->srv == NET_SRV_CONNECTED)
  {
    if (n->sent_valid && n->sent_age_s < 3600U)
      snprintf(l2, sizeof(l2), "%s: BAGLI (%lu sn once)", NET_SERVER_NAME, (unsigned long)n->sent_age_s);
    else
      snprintf(l2, sizeof(l2), "%s: BAGLI", NET_SERVER_NAME);
    t2 = UI_TONE_OK;
  }
  else
  {
    snprintf(l2, sizeof(l2), "%s: BAGLANTI HATASI", NET_SERVER_NAME);
    t2 = UI_TONE_ERR;
  }

  if (force || t1 != lt1 || t2 != lt2 || strcmp(l1, last1) != 0 || strcmp(l2, last2) != 0)
  {
    UI_DrawNetStatus(l1, t1, l2, t2);
    strcpy(last1, l1); strcpy(last2, l2);
    lt1 = t1; lt2 = t2;
  }
}

/* Ana ekrandaki deney paneli + DENEY / KAYIT butonlarinin durumu */
static void UI_UpdateExp(uint8_t force)
{
  static uint8_t last_state = 0xFF;
  const Exp_Status *e = Exp_GetStatus();
  char l1[48], l2[64], a[20];
  const char *badge;
  UI_Tone tone;

  if (force || (uint8_t)e->state != last_state)
  {
    last_state = (uint8_t)e->state;
    UI_SetRecLocked((e->state == EXP_RUNNING || e->state == EXP_PAUSED) ? 1U : 0U);
    UI_SetRecording(LogCtrl_IsActive());
    UI_SetButtonLabel(UI_BTN_EXP, "DENEY", (e->state == EXP_IDLE) ? "menu" : "izle", UI_STYLE_ACCENT);
    UI_DrawButton(UI_BTN_EXP, 0U);
    UI_DrawButton(UI_BTN_REC, 0U);
  }

  if (e->state == EXP_IDLE)
  {
    UI_DrawExpPanel("DENEY: --", "BOSTA", UI_TONE_MUTED, "Test secmek icin DENEY butonuna dokunun", UI_TONE_MUTED);
    return;
  }

  if (e->full) snprintf(l1, sizeof(l1), "DENEY: %s [%u/%u]", Exp_ProcName(e->proc), e->stage + 1U, e->stages);
  else         snprintf(l1, sizeof(l1), "DENEY: %s", Exp_ProcName(e->proc));

  if (e->safety != EXP_SAFE_OK)       { badge = "GUVENLIK";     tone = UI_TONE_ERR;  }
  else if (e->state == EXP_RUNNING && e->limit) { badge = "SINIRLI"; tone = UI_TONE_WARN; }
  else if (e->state == EXP_RUNNING)   { badge = "CALISIYOR";    tone = UI_TONE_OK;   }
  else if (e->state == EXP_PAUSED)    { badge = "DURAKLATILDI"; tone = UI_TONE_WARN; }
  else                                { badge = "TAMAMLANDI";   tone = UI_TONE_INFO; }

  Exp_FormatDuration(a, sizeof(a), (e->state == EXP_DONE) ? 0U : e->total_left_s);
  if (e->state == EXP_DONE)
    snprintf(l2, sizeof(l2), "Tamamlandi - izle > TAMAM ile kapatin");
  else if (e->closed)
    snprintf(l2, sizeof(l2), "SP %d.%d  Adim %u  Kalan %s", e->sp_x10 / 10, e->sp_x10 % 10, e->phase, a);
  else
  {
    char g[20];
    Exp_FormatDuration(g, sizeof(g), e->elapsed_s);
    snprintf(l2, sizeof(l2), "Adim %u  Gecen %s  Kalan %s", e->phase, g, a);
  }
  UI_DrawExpPanel(l1, badge, tone, l2, (e->safety != EXP_SAFE_OK) ? UI_TONE_ERR : UI_TONE_TEXT);
}

/* HAL UART geri cagirmalari: ilgili module yonlendirilir */
void HAL_UART_RxCpltCallback(UART_HandleTypeDef *huart)
{
  Peltier_UartRxCplt(huart);
  Debug_UartRxCplt(huart);
}

void HAL_UART_ErrorCallback(UART_HandleTypeDef *huart)
{
  Peltier_UartError(huart);
  Debug_UartError(huart);
}

/* USER CODE END 4 */

void Error_Handler(void)
{
  __disable_irq();
  while (1)
  {
  }
}
